AUTOSAR XML (schema 00049)
package /Systems
  system SYSTEM_XDIS: container-i-pdu-header-byte-order=big-endian, ecu-extract-version=2023.29.00, pnc-vector-length=7, pnc-vector-offset=1, system-version=2023.29.00
    system mapping SYSTEM_XDIS_MPPNG
      data-mappings:
        sender-receiver-to-signal-mapping={data-element=ECU_RBTM_FL_STAR_3_2020_ST3.R_PN14_ProdMd_Stat_ST3.PN14_ProdMd_Stat_ST3, system-signal=PN14_ProdMd_Stat_ST3}
        sender-receiver-to-signal-group-mapping={data-element=ECU_RBTM_FL_STAR_3_2020_ST3.R_PT4_PTCoor4_Pr5_ST3.PT4_PTCoor4_Pr5_ST3, signal-group=PT4_PTCoor4_Pr5_ST3_af4fxb1ykieox3itqdfzs0kpb, type-mapping=sender-rec-record-type-mapping=record-element-mappings=[{application-record-element=PT4_PTCoor_PT_Rdy_ST3, system-signal=PT4_PTCoor_PT_Rdy_ST3}, {application-record-element=PT4_PTCoor_EngStartPN14_Stat_ST3, system-signal=PT4_PTCoor_EngStartPN14_Stat_ST3}]}
        sender-receiver-to-signal-mapping={variation-point=post-build-variant-condition{matching-criterion=SideAllocation, value=0}, data-element=ECU_RBTM_FL_STAR_3_2020_ST3.P_RBTMFL_SP_ActvClient_ST35.RBTMFL_SP_ActvClient_ST35, system-signal=RBTMFL_SP_ActvClient_ST35}
        sender-receiver-to-signal-group-mapping={data-element=ECU_RBTM_FL_STAR_3_2020_ST3.R_EVC_CfgList_01_08_Pr5_ST3.EVC_CfgList_01_08_Pr5_ST3, signal-group=EVC_CfgList_01_08_Pr5_ST3_co3q1mwsf7pwxo2ix5jryc04x, type-mapping=sender-rec-record-type-mapping=record-element-mappings=[{application-record-element=EVC_List03_StStyle_ST3, system-signal=EVC_List03_StStyle_ST3}, {application-record-element=EVC_CfgList_01_08_Stat_ST3, system-signal=EVC_CfgList_01_08_Stat_ST3}]}
        sender-receiver-to-signal-mapping={data-element=ECU_RBTM_FL_STAR_3_2020_ST3.R_VehSpd_Disp_ST3.VehSpd_Disp_ST3, system-signal=VehSpd_Disp_ST3}
        sender-receiver-to-signal-mapping={variation-point=post-build-variant-condition{matching-criterion=SideAllocation, value=0}, data-element=ECU_RBTM_FL_STAR_3_2020_ST3.P_Awake_Ignition_On_RBTM_FL_ST3.Awake_Ignition_On_RBTM_FL_ST3, system-signal=Awake_Ignition_On_RBTM_FL_ST3}
        sender-receiver-to-signal-mapping={variation-point=post-build-variant-condition{matching-criterion=SideAllocation, value=0}, data-element=ECU_RBTM_FL_STAR_3_2020_ST3.R_RevBltTns_FR_SafeCyc_Actv_ST3.RevBltTns_FR_SafeCyc_Actv_ST3, system-signal=RevBltTns_FR_SafeCyc_Actv_ST3}
        sender-receiver-to-signal-mapping={data-element=ECU_RBTM_FL_STAR_3_2020_ST3.R_DidA_ExtTest_Pres_ST3.DidA_ExtTest_Pres_ST3, system-signal=DidA_ExtTest_Pres_ST3}
        sender-receiver-to-signal-group-mapping={data-element=ECU_RBTM_FL_STAR_3_2020_ST3.R_PT4_PTCoor_DrvPosn_Gear_Pr5_ST3.PT4_PTCoor_DrvPosn_Gear_Pr5_ST3, signal-group=PT4_PTCoor_DrvPosn_Gear_Pr5_ST3_5p8cvrni3ypvuac33rj2asfy9, type-mapping=sender-rec-record-type-mapping=sender-rec-record-element-mapping{application-record-element=PT4_PTCoor_DrvPosn_Stat_ST3, system-signal=PT4_PTCoor_DrvPosn_Stat_ST3}}
        sender-receiver-to-signal-group-mapping={data-element=ECU_RBTM_FL_STAR_3_2020_ST3.R_ADAS_Posn_ST3.ADAS_Posn_ST3, signal-group=ADAS_Posn_ST3_cre9f2x2lehhx0k4gxnl4u9sg, type-mapping=sender-rec-record-type-mapping=record-element-mappings=[{application-record-element=ADAS_Posn_Idx_ST3, system-signal=ADAS_Posn_Idx_ST3}, {application-record-element=ADAS_Posn_Offset_ST3, system-signal=ADAS_Posn_Offset_ST3}, {application-record-element=ADAS_Posn_Age_ST3, system-signal=ADAS_Posn_Age_ST3}, {application-record-element=ADAS_Posn_Spd_ST3, system-signal=ADAS_Posn_Spd_ST3}, {application-record-element=ADAS_Posn_PathIdx_ST3, system-signal=ADAS_Posn_PathIdx_ST3}]}
        sender-receiver-to-signal-mapping={data-element=ECU_RBTM_FL_STAR_3_2020_ST3.R_ADAS_Prediction_MsgTyp_ST3.ADAS_Prediction_MsgTyp_ST3, system-signal=ADAS_Prediction_MsgTyp_ST3}
        sender-receiver-to-signal-mapping={variation-point=post-build-variant-condition{matching-criterion=SideAllocation, value=0}, data-element=ECU_RBTM_FL_STAR_3_2020_ST3.R_PS_Curve_FL_Rq_HU_ST3.PS_Curve_FL_Rq_HU_ST3, system-signal=PS_Curve_FL_Rq_HU_ST3}
        sender-receiver-to-signal-mapping={variation-point=post-build-variant-condition{matching-criterion=SideAllocation, value=0}, data-element=ECU_RBTM_FL_STAR_3_2020_ST3.P_RevBltTns_FL_ComCyc_Actv_ST3.RevBltTns_FL_ComCyc_Actv_ST3, system-signal=RevBltTns_FL_ComCyc_Actv_ST3}
        sender-receiver-to-signal-group-mapping={data-element=ECU_RBTM_FL_STAR_3_2020_ST3.R_ORC_Impact3_Pr5_ST3.ORC_Impact3_Pr5_ST3, signal-group=ORC_Impact3_Pr5_ST3_c4pqnkonfjwv3uiohsxhe9dwu, type-mapping=sender-rec-record-type-mapping=record-element-mappings=[{application-record-element=Impact_S2_ST3, system-signal=Impact_S2_ST3}, {application-record-element=Impact_RO_type2_ST3, system-signal=Impact_RO_type2_ST3}, {application-record-element=Impact_F2_ST3, system-signal=Impact_F2_ST3}, {application-record-element=Impact_F1_ST3, system-signal=Impact_F1_ST3}, {application-record-element=Impact_X_ST3, system-signal=Impact_X_ST3}, {application-record-element=SQC_ORC_Impact3_Pr5_ST3, system-signal=SQC_ORC_Impact3_Pr5_ST3}, {application-record-element=Impact_F3_ST3, system-signal=Impact_F3_ST3}, {application-record-element=Impact_RO_type1_ST3, system-signal=Impact_RO_type1_ST3}, {application-record-element=Impact_S1_ST3, system-signal=Impact_S1_ST3}, {application-record-element=CRC_ORC_Impact3_Pr5_ST3, system-signal=CRC_ORC_Impact3_Pr5_ST3}]}
        sender-receiver-to-signal-group-mapping={data-element=ECU_RBTM_FL_STAR_3_2020_ST3.R_VSS_TP_Auth_ST3.VSS_TP_Auth_ST3, signal-group=VSS_TP_Auth_ST3_6j4id7sghlvlbroli4wjozjik, type-mapping=sender-rec-array-type-mapping=array-element-mappings=[{indexed-array-element={application-array-element=ARRAY_ELEMENT, index=0}, system-signal=VSS_TP_Auth_0_ST3}, {indexed-array-element={application-array-element=ARRAY_ELEMENT, index=1}, system-signal=VSS_TP_Auth_1_ST3}, {indexed-array-element={application-array-element=ARRAY_ELEMENT, index=2}, system-signal=VSS_TP_Auth_2_ST3}, {indexed-array-element={application-array-element=ARRAY_ELEMENT, index=3}, system-signal=VSS_TP_Auth_3_ST3}, {indexed-array-element={application-array-element=ARRAY_ELEMENT, index=4}, system-signal=VSS_TP_Auth_4_ST3}, {indexed-array-element={application-array-element=ARRAY_ELEMENT, index=5}, system-signal=VSS_TP_Auth_5_ST3}, {indexed-array-element={application-array-element=ARRAY_ELEMENT, index=6}, system-signal=VSS_TP_Auth_6_ST3}, {indexed-array-element={application-array-element=ARRAY_ELEMENT, index=7}, system-signal=VSS_TP_Auth_7_ST3}]}
        sender-receiver-to-signal-mapping={data-element=ECU_RBTM_FL_STAR_3_2020_ST3.R_PN14_DDP_Sw_Stat_ST3.PN14_DDP_Sw_Stat_ST3, system-signal=PN14_DDP_Sw_Stat_ST3}
        sender-receiver-to-signal-mapping={data-element=ECU_RBTM_FL_STAR_3_2020_ST3.R_Navi_RouteGuidance_Stat_ST3.Navi_RouteGuidance_Stat_ST3, system-signal=Navi_RouteGuidance_Stat_ST3}
        sender-receiver-to-signal-group-mapping={data-element=ECU_RBTM_FL_STAR_3_2020_ST3.R_DI_Odo_Pr5_ST3.DI_Odo_Pr5_ST3, signal-group=DI_Odo_Pr5_ST3_e68xmtlkywxgxsdwekdjjhw3t, type-mapping=sender-rec-record-type-mapping=sender-rec-record-element-mapping{application-record-element=Odo_ST3, system-signal=Odo_ST3}}
        sender-receiver-to-signal-mapping={variation-point=post-build-variant-condition{matching-criterion=SideAllocation, value=0}, data-element=ECU_RBTM_FL_STAR_3_2020_ST3.P_BltSlckDec_Md_XX_Stat_ST3.BltSlckDec_Md_XX_Stat_ST3, system-signal=BltSlckDec_Md_FL_Stat_ST3}
        sender-receiver-to-signal-mapping={variation-point=post-build-variant-condition{matching-criterion=SideAllocation, value=0}, data-element=ECU_RBTM_FL_STAR_3_2020_ST3.P_RevBltTns_FL_SafeCyc_Actv_ST3.RevBltTns_FL_SafeCyc_Actv_ST3, system-signal=RevBltTns_FL_SafeCyc_Actv_ST3}
        sender-receiver-to-signal-mapping={data-element=ECU_RBTM_FL_STAR_3_2020_ST3.R_PN14_TransMd_Stat_ST3.PN14_TransMd_Stat_ST3, system-signal=PN14_TransMd_Stat_ST3}
        sender-receiver-to-signal-group-mapping={data-element=ECU_RBTM_FL_STAR_3_2020_ST3.R_VSS_TP_RealTmOffset_ST3.VSS_TP_RealTmOffset_ST3, signal-group=VSS_TP_RealTmOffset_ST3_1t7vc44gftc0wv35k5kgc2in9, type-mapping=sender-rec-array-type-mapping=array-element-mappings=[{indexed-array-element={application-array-element=ARRAY_ELEMENT, index=0}, system-signal=VSS_TP_RealTmOffset_0_ST3}, {indexed-array-element={application-array-element=ARRAY_ELEMENT, index=1}, system-signal=VSS_TP_RealTmOffset_1_ST3}, {indexed-array-element={application-array-element=ARRAY_ELEMENT, index=2}, system-signal=VSS_TP_RealTmOffset_2_ST3}, {indexed-array-element={application-array-element=ARRAY_ELEMENT, index=3}, system-signal=VSS_TP_RealTmOffset_3_ST3}, {indexed-array-element={application-array-element=ARRAY_ELEMENT, index=4}, system-signal=VSS_TP_RealTmOffset_4_ST3}, {indexed-array-element={application-array-element=ARRAY_ELEMENT, index=5}, system-signal=VSS_TP_RealTmOffset_5_ST3}, {indexed-array-element={application-array-element=ARRAY_ELEMENT, index=6}, system-signal=VSS_TP_RealTmOffset_6_ST3}, {indexed-array-element={application-array-element=ARRAY_ELEMENT, index=7}, system-signal=VSS_TP_RealTmOffset_7_ST3}]}
        sender-receiver-to-signal-group-mapping={data-element=ECU_RBTM_FL_STAR_3_2020_ST3.R_PT4_PTCoor9_Pr5_ST3.PT4_PTCoor9_Pr5_ST3, signal-group=PT4_PTCoor9_Pr5_ST3_6r95o81sst3tk9w2lzz600cw3, type-mapping=sender-rec-record-type-mapping=sender-rec-record-element-mapping{application-record-element=PT4_PTCoor_Accel_Md_ST3, system-signal=PT4_PTCoor_Accel_Md_ST3}}
        sender-receiver-to-signal-mapping={variation-point=post-build-variant-condition{matching-criterion=SideAllocation, value=0}, data-element=ECU_RBTM_FL_STAR_3_2020_ST3.P_RBTM_FL_Disp_Rq_ST3.RBTM_FL_Disp_Rq_ST3, system-signal=RBTM_FL_Disp_Rq_ST3}
        sender-receiver-to-signal-mapping={variation-point=post-build-variant-condition{matching-criterion=SideAllocation, value=0}, data-element=ECU_RBTM_FL_STAR_3_2020_ST3.P_PS_Curve_FL_Stat_ST3.PS_Curve_FL_Stat_ST3, system-signal=PS_Curve_FL_Stat_ST3}
        sender-receiver-to-signal-mapping={variation-point=post-build-variant-condition{matching-criterion=SideAllocation, value=0}, data-element=ECU_RBTM_FL_STAR_3_2020_ST3.R_BeltHdOvr_XX_Stat_ST3.BeltHdOvr_XX_Stat_ST3, system-signal=BeltHdOvr_FL_Stat_ST3}
        sender-receiver-to-signal-mapping={variation-point=post-build-variant-condition{matching-criterion=SideAllocation, value=0}, data-element=ECU_RBTM_FL_STAR_3_2020_ST3.P_ECU_Id_RBTM_FL_ST3.ECU_Id_RBTM_FL_ST3, system-signal=ECU_Id_RBTM_FL_ST3}
        sender-receiver-to-signal-group-mapping={variation-point=post-build-variant-condition{matching-criterion=SideAllocation, value=0}, data-element=ECU_RBTM_FL_STAR_3_2020_ST3.P_ROE.ROE_XX_ST3, signal-group=ROE_RBTM_FL_ST3_6e0rxnifai2txra0wamb18g4m, type-mapping=sender-rec-record-type-mapping=record-element-mappings=[{application-record-element=ROE_0, system-signal=ROE_0_RBTM_FL_ST3}, {application-record-element=ROE_4, system-signal=ROE_4_RBTM_FL_ST3}, {application-record-element=ROE_3, system-signal=ROE_3_RBTM_FL_ST3}, {application-record-element=ROE_1, system-signal=ROE_1_RBTM_FL_ST3}, {application-record-element=ROE_2, system-signal=ROE_2_RBTM_FL_ST3}, {application-record-element=ROE_5, system-signal=ROE_5_RBTM_FL_ST3}, {application-record-element=ROE_6, system-signal=ROE_6_RBTM_FL_ST3}, {application-record-element=ROE_7, system-signal=ROE_7_RBTM_FL_ST3}]}
        sender-receiver-to-signal-group-mapping={data-element=ECU_RBTM_FL_STAR_3_2020_ST3.R_Bckl_Sw_Fx_Stat_Pr5_ST3.Bckl_Sw_Fx_Stat_Pr5_ST3, signal-group=Bckl_Sw_Fx_Stat_Pr5_ST3_dihag5a55iw4h5qk539fx0kup, type-mapping=sender-rec-record-type-mapping=record-element-mappings=[{application-record-element=Rsrv1_Bckl_Sw_Fx_Stat_ST3, system-signal=Rsrv1_Bckl_Sw_Fx_Stat_ST3}, {application-record-element=Bckl_Sw_D_Stat_ST3, system-signal=Bckl_Sw_D_Stat_ST3}, {application-record-element=Bckl_Sw_FP_Stat_ST3, system-signal=Bckl_Sw_FP_Stat_ST3}, {application-record-element=CRC_Bckl_Sw_Fx_Stat_Pr5_ST3, system-signal=CRC_Bckl_Sw_Fx_Stat_Pr5_ST3}, {application-record-element=SQC_Bckl_Sw_Fx_Stat_Pr5_ST3, system-signal=SQC_Bckl_Sw_Fx_Stat_Pr5_ST3}]}
        sender-receiver-to-signal-mapping={data-element=ECU_RBTM_FL_STAR_3_2020_ST3.R_PN14_SupBat_Volt_ST3.PN14_SupBat_Volt_ST3, system-signal=PN14_SupBat_Volt_ST3}
        sender-receiver-to-signal-mapping={variation-point=post-build-variant-condition{matching-criterion=SideAllocation, value=0}, data-element=ECU_RBTM_FL_STAR_3_2020_ST3.R_RevBltTns_FR_ComCyc_Actv_ST3.RevBltTns_FR_ComCyc_Actv_ST3, system-signal=RevBltTns_FR_ComCyc_Actv_ST3}
        sender-receiver-to-signal-mapping={variation-point=post-build-variant-condition{matching-criterion=SideAllocation, value=0}, data-element=ECU_RBTM_FL_STAR_3_2020_ST3.P_RBTMFL_SP_FctPrecond_Stat_ST35.RBTMFL_SP_FctPrecond_Stat_ST35, system-signal=RBTMFL_SP_FctPrecond_Stat_ST35}
        sender-receiver-to-signal-mapping={variation-point=post-build-variant-condition{matching-criterion=SideAllocation, value=0}, data-element=ECU_RBTM_FL_STAR_3_2020_ST3.P_Awake_Diag_Actv_RBTM_FL_ST3.Awake_Diag_Actv_RBTM_FL_ST3, system-signal=Awake_Diag_Actv_RBTM_FL_ST3}
        sender-receiver-to-signal-group-mapping={data-element=ECU_RBTM_FL_STAR_3_2020_ST3.R_Ign_Stat_Pr5_ST3.Ign_Stat_Pr5_ST3, signal-group=Ign_Stat_Pr5_ST3_csgs1dv6drms80o1i9p49677w, type-mapping=sender-rec-record-type-mapping=record-element-mappings=[{application-record-element=KG_StartSw_Psd_ST3, system-signal=KG_StartSw_Psd_ST3}, {application-record-element=CRC_Ign_Stat_Pr5_ST3, system-signal=CRC_Ign_Stat_Pr5_ST3}, {application-record-element=Veh_Op_Mode_ST3, system-signal=Veh_Op_Mode_ST3}, {application-record-element=ISw_Stat_ST3, system-signal=ISw_Stat_ST3}, {application-record-element=SQC_Ign_Stat_Pr5_ST3, system-signal=SQC_Ign_Stat_Pr5_ST3}]}
        sender-receiver-to-signal-group-mapping={data-element=ECU_RBTM_FL_STAR_3_2020_ST3.R_VSS_TP_VIN_ST3.VSS_TP_VIN_ST3, signal-group=VSS_TP_VIN_ST3_bz1xsv84cxzl09j028gn39p69, type-mapping=sender-rec-array-type-mapping=array-element-mappings=[{indexed-array-element={application-array-element=ARRAY_ELEMENT, index=0}, system-signal=VSS_TP_VIN_0_ST3}, {indexed-array-element={application-array-element=ARRAY_ELEMENT, index=1}, system-signal=VSS_TP_VIN_1_ST3}, {indexed-array-element={application-array-element=ARRAY_ELEMENT, index=2}, system-signal=VSS_TP_VIN_2_ST3}, {indexed-array-element={application-array-element=ARRAY_ELEMENT, index=3}, system-signal=VSS_TP_VIN_3_ST3}, {indexed-array-element={application-array-element=ARRAY_ELEMENT, index=4}, system-signal=VSS_TP_VIN_4_ST3}, {indexed-array-element={application-array-element=ARRAY_ELEMENT, index=5}, system-signal=VSS_TP_VIN_5_ST3}, {indexed-array-element={application-array-element=ARRAY_ELEMENT, index=6}, system-signal=VSS_TP_VIN_6_ST3}, {indexed-array-element={application-array-element=ARRAY_ELEMENT, index=7}, system-signal=VSS_TP_VIN_7_ST3}]}
        sender-receiver-to-signal-group-mapping={data-element=ECU_RBTM_FL_STAR_3_2020_ST3.R_CLkS_DrRltch_Stat_Pr5_ST3.CLkS_DrRltch_Stat_Pr5_ST3, signal-group=CLkS_DrRltch_Stat_Pr5_ST3_7at68qvnk0r9npofyykyfq82v, type-mapping=sender-rec-record-type-mapping=record-element-mappings=[{application-record-element=DrRLtch_FL_Stat_ST3, system-signal=DrRLtch_FL_Stat_ST3}, {application-record-element=DrRLtch_FR_Stat_ST3, system-signal=DrRLtch_FR_Stat_ST3}]}
        sender-receiver-to-signal-mapping={variation-point=post-build-variant-condition{matching-criterion=SideAllocation, value=0}, data-element=ECU_RBTM_FL_STAR_3_2020_ST3.P_WakeupRsn_RBTM_FL_ST3.WakeupRsn_RBTM_FL_ST3, system-signal=WakeupRsn_RBTM_FL_ST3}
        sender-receiver-to-signal-group-mapping={data-element=ECU_RBTM_FL_STAR_3_2020_ST3.R_ADAS_Profile_Short_CurvLn_ST3.ADAS_Profile_Short_CurvLn_ST3, signal-group=ADAS_Profile_Short_CurvLn_ST3_96e9ejcafisp13h7moqj5malh, type-mapping=sender-rec-record-type-mapping=record-element-mappings=[{application-record-element=ADAS_ProfShort_Value0_CL_ST3, system-signal=ADAS_ProfShort_Value0_CL_ST3}, {application-record-element=ADAS_ProfShort_Dist1_CL_ST3, system-signal=ADAS_ProfShort_Dist1_CL_ST3}, {application-record-element=ADAS_ProfShort_PathIdx_CL_ST3, system-signal=ADAS_ProfShort_PathIdx_CL_ST3}, {application-record-element=ADAS_ProfShort_Value1_CL_ST3, system-signal=ADAS_ProfShort_Value1_CL_ST3}, {application-record-element=ADAS_ProfShort_Offset_CL_ST3, system-signal=ADAS_ProfShort_Offset_CL_ST3}, {application-record-element=ADAS_ProfShort_ReTr_CL_ST3, system-signal=ADAS_ProfShort_ReTr_CL_ST3}]}
        sender-receiver-to-signal-mapping={data-element=ECU_RBTM_FL_STAR_3_2020_ST3.R_ADAS_ProfShort_ProfTyp_ST3.ADAS_ProfShort_ProfTyp_ST3, system-signal=ADAS_ProfShort_ProfTyp_ST3}
        sender-receiver-to-signal-group-mapping={data-element=ECU_RBTM_FL_STAR_3_2020_ST3.R_ELC_Lvr_Stat_Pr5_ST3.ELC_Lvr_Stat_Pr5_ST3, signal-group=ELC_Lvr_Stat_Pr5_ST3_7b68ktfwrvsk1oyozi7cntryn, type-mapping=sender-rec-record-type-mapping=sender-rec-record-element-mapping{application-record-element=ELC_TurnIndLvr_Stat_ST3, system-signal=ELC_TurnIndLvr_Stat_ST3}}
        sender-receiver-to-signal-group-mapping={data-element=ECU_RBTM_FL_STAR_3_2020_ST3.R_PresfAct_Adj_Pr5_ST3.PresfAct_Adj_Pr5_ST3, signal-group=PresfAct_Adj_Pr5_ST3_2joar1a41xrgjqab60epnbplm, type-mapping=sender-rec-record-type-mapping=record-element-mappings=[{application-record-element=CRC_PresfAct_Adj_Pr5_ST3, system-signal=CRC_PresfAct_Adj_Pr5_ST3}, {application-record-element=Presf_FricCoeff_Estim_ST3, system-signal=Presf_FricCoeff_Estim_ST3}, {application-record-element=Presf_Snd_Rq_ST3, system-signal=Presf_Snd_Rq_ST3}, {application-record-element=Presf_Lvl_ST3, system-signal=Presf_Lvl_ST3}, {application-record-element=PresfAct_TensSupp_Rq_ST3, system-signal=PresfAct_TensSupp_Rq_ST3}, {application-record-element=PresfAccelReset_NotExcd_ST3, system-signal=PresfAccelReset_NotExcd_ST3}, {application-record-element=Presf_Fric_Fctr_Lo_ST3, system-signal=Presf_Fric_Fctr_Lo_ST3}, {application-record-element=Rsrv6_Presf_Adj_ST3, system-signal=Rsrv6_Presf_Adj_ST3}, {application-record-element=Presf_Enbl_ST3, system-signal=Presf_Enbl_ST3}, {application-record-element=PresfAct_Adj_Rq_ST3, system-signal=PresfAct_Adj_Rq_ST3}, {application-record-element=SQC_PresfAct_Adj_Pr5_ST3, system-signal=SQC_PresfAct_Adj_Pr5_ST3}]}
        sender-receiver-to-signal-group-mapping={data-element=ECU_RBTM_FL_STAR_3_2020_ST3.R_VSS_TP_SharedSecret_ST3.VSS_TP_SharedSecret_ST3, signal-group=VSS_TP_SharedSecret_ST3_8pj4t8t4rm3tw3pk5hj7vonti, type-mapping=sender-rec-array-type-mapping=array-element-mappings=[{indexed-array-element={application-array-element=ARRAY_ELEMENT, index=0}, system-signal=VSS_TP_SharedSecret_0_ST3}, {indexed-array-element={application-array-element=ARRAY_ELEMENT, index=1}, system-signal=VSS_TP_SharedSecret_1_ST3}, {indexed-array-element={application-array-element=ARRAY_ELEMENT, index=2}, system-signal=VSS_TP_SharedSecret_2_ST3}, {indexed-array-element={application-array-element=ARRAY_ELEMENT, index=3}, system-signal=VSS_TP_SharedSecret_3_ST3}, {indexed-array-element={application-array-element=ARRAY_ELEMENT, index=4}, system-signal=VSS_TP_SharedSecret_4_ST3}, {indexed-array-element={application-array-element=ARRAY_ELEMENT, index=5}, system-signal=VSS_TP_SharedSecret_5_ST3}, {indexed-array-element={application-array-element=ARRAY_ELEMENT, index=6}, system-signal=VSS_TP_SharedSecret_6_ST3}, {indexed-array-element={application-array-element=ARRAY_ELEMENT, index=7}, system-signal=VSS_TP_SharedSecret_7_ST3}]}
        sender-receiver-to-signal-group-mapping={data-element=ECU_RBTM_FL_STAR_3_2020_ST3.R_DPC_Md_Rq_ESP_Pr5_ST3.DPC_Md_Rq_ESP_Pr5_ST3, signal-group=DPC_Md_Rq_ESP_Pr5_ST3_dcsny138uwpesz5bmssj1scqi, type-mapping=sender-rec-record-type-mapping=sender-rec-record-element-mapping{application-record-element=DPC_Md_PT_Rq_ST3, system-signal=DPC_Md_PT_Rq_ST3}}
        sender-receiver-to-signal-group-mapping={variation-point=post-build-variant-condition{matching-criterion=SideAllocation, value=0}, data-element=ECU_RBTM_FL_STAR_3_2020_ST3.P_Meas_RBTM_FL_ST3.Meas8_RBTM_FL_ST3, signal-group=Meas8_RBTM_FL_ST3_72jyquhuktrmjm0hkqempja37, type-mapping=sender-rec-record-type-mapping=record-element-mappings=[{application-record-element=Meas_RBTM_FL_02, system-signal=Meas_RBTM_FL_02_ST3}, {application-record-element=Meas_RBTM_FL_08, system-signal=Meas_RBTM_FL_08_ST3}, {application-record-element=Meas_RBTM_FL_03, system-signal=Meas_RBTM_FL_03_ST3}, {application-record-element=Meas_RBTM_FL_06, system-signal=Meas_RBTM_FL_06_ST3}, {application-record-element=Meas_RBTM_FL_04, system-signal=Meas_RBTM_FL_04_ST3}, {application-record-element=Meas_RBTM_FL_07, system-signal=Meas_RBTM_FL_07_ST3}, {application-record-element=Meas_RBTM_FL_05, system-signal=Meas_RBTM_FL_05_ST3}, {application-record-element=Meas_RBTM_FL_01, system-signal=Meas_RBTM_FL_01_ST3}]}
        sender-receiver-to-signal-group-mapping={data-element=ECU_RBTM_FL_STAR_3_2020_ST3.R_ORC_Impact2_Pr5_ST3.ORC_Impact2_Pr5_ST3, signal-group=ORC_Impact2_Pr5_ST3_b9l09rrslyv7vj3o92j69irnd, type-mapping=sender-rec-record-type-mapping=sender-rec-record-element-mapping{application-record-element=Impact_Y_ST3, system-signal=Impact_Y_ST3}}
        sender-receiver-to-signal-mapping={variation-point=post-build-variant-condition{matching-criterion=SideAllocation, value=0}, data-element=ECU_RBTM_FL_STAR_3_2020_ST3.P_RBTMFL_Actv_Lvl_ST35.RBTMFL_Actv_Lvl_ST35, system-signal=RBTMFL_Actv_Lvl_ST35}
        sender-receiver-to-signal-group-mapping={variation-point=post-build-variant-condition{matching-criterion=SideAllocation, value=0}, data-element=ECU_RBTM_FL_STAR_3_2020_ST3.R_Develop8_Rq_RBTM_FL_ST3.Develop8_Rq_RBTM_FL_ST3, signal-group=Develop8_Rq_RBTM_FL_ST3_48g6nu8rjjp9s4bhq1x3pz06u, type-mapping=sender-rec-record-type-mapping=record-element-mappings=[{application-record-element=Develop_Rq_RBTM_FL_01, system-signal=Develop_Rq_RBTM_FL_01_ST3}, {application-record-element=Develop_Rq_RBTM_FL_03, system-signal=Develop_Rq_RBTM_FL_03_ST3}, {application-record-element=Develop_Rq_RBTM_FL_04, system-signal=Develop_Rq_RBTM_FL_04_ST3}, {application-record-element=Develop_Rq_RBTM_FL_02, system-signal=Develop_Rq_RBTM_FL_02_ST3}, {application-record-element=Develop_Rq_RBTM_FL_07, system-signal=Develop_Rq_RBTM_FL_07_ST3}, {application-record-element=Develop_Rq_RBTM_FL_08, system-signal=Develop_Rq_RBTM_FL_08_ST3}, {application-record-element=Develop_Rq_RBTM_FL_06, system-signal=Develop_Rq_RBTM_FL_06_ST3}, {application-record-element=Develop_Rq_RBTM_FL_05, system-signal=Develop_Rq_RBTM_FL_05_ST3}]}
        sender-receiver-to-signal-group-mapping={variation-point=post-build-variant-condition{matching-criterion=SideAllocation, value=0}, data-element=ECU_RBTM_FL_STAR_3_2020_ST3.P_Develop8_Rs_RBTM_FL_ST3.Develop8_Rs_RBTM_FL_ST3, signal-group=Develop8_Rs_RBTM_FL_ST3_7jg1r8p1skn6yj1t9z2s157vt, type-mapping=sender-rec-record-type-mapping=record-element-mappings=[{application-record-element=Develop_Rs_RBTM_FL_04, system-signal=Develop_Rs_RBTM_FL_04_ST3}, {application-record-element=Develop_Rs_RBTM_FL_02, system-signal=Develop_Rs_RBTM_FL_02_ST3}, {application-record-element=Develop_Rs_RBTM_FL_08, system-signal=Develop_Rs_RBTM_FL_08_ST3}, {application-record-element=Develop_Rs_RBTM_FL_05, system-signal=Develop_Rs_RBTM_FL_05_ST3}, {application-record-element=Develop_Rs_RBTM_FL_03, system-signal=Develop_Rs_RBTM_FL_03_ST3}, {application-record-element=Develop_Rs_RBTM_FL_06, system-signal=Develop_Rs_RBTM_FL_06_ST3}, {application-record-element=Develop_Rs_RBTM_FL_01, system-signal=Develop_Rs_RBTM_FL_01_ST3}, {application-record-element=Develop_Rs_RBTM_FL_07, system-signal=Develop_Rs_RBTM_FL_07_ST3}]}
        sender-receiver-to-signal-mapping={variation-point=post-build-variant-condition{matching-criterion=SideAllocation, value=0}, data-element=ECU_RBTM_FL_STAR_3_2020_ST3.P_Awake_NwStart_RBTM_FL_ST3.Awake_NwStart_RBTM_FL_ST3, system-signal=Awake_NwStart_RBTM_FL_ST3}
        sender-receiver-to-signal-mapping={variation-point=post-build-variant-condition{matching-criterion=SideAllocation, value=0}, data-element=ECU_RBTM_FL_STAR_3_2020_ST3.P_RBTM_FL_Tgl_ST3.RBTM_FL_Tgl_ST3, system-signal=RBTM_FL_Tgl_ST3}
        sender-receiver-to-signal-group-mapping={data-element=ECU_RBTM_FL_STAR_3_2020_ST3.R_ADAS_Meta_ST3.ADAS_Meta_ST3, signal-group=ADAS_Meta_ST3_40sly585w5zu8pqjwib3nr7y7, type-mapping=sender-rec-record-type-mapping=record-element-mappings=[{application-record-element=ADAS_Meta_CountryCode_ST3, system-signal=ADAS_Meta_CountryCode_ST3}, {application-record-element=ADAS_Meta_RegionCode_ST3, system-signal=ADAS_Meta_RegionCode_ST3}]}
        sender-receiver-to-signal-mapping={data-element=ECU_RBTM_FL_STAR_3_2020_ST3.R_BltSlckDec_Md_Rq_HU_ST3.BltSlckDec_Md_Rq_HU_ST3, system-signal=BltSlckDec_Md_Rq_HU_ST3}
        sender-receiver-to-signal-group-mapping={data-element=ECU_RBTM_FL_STAR_3_2020_ST3.R_VSS_TP_SecTickCount_ST3.VSS_TP_SecTickCount_ST3, signal-group=VSS_TP_SecTickCount_Lvl2_ST3_9eubq13iosat764o0lqh5xb6r, type-mapping=sender-rec-array-type-mapping=array-element-mappings=[{indexed-array-element={application-array-element=ARRAY_ELEMENT, index=0}, system-signal=VSS_TP_SecTickCount_Lvl2_0_ST3}, {indexed-array-element={application-array-element=ARRAY_ELEMENT, index=1}, system-signal=VSS_TP_SecTickCount_Lvl2_1_ST3}, {indexed-array-element={application-array-element=ARRAY_ELEMENT, index=2}, system-signal=VSS_TP_SecTickCount_Lvl2_2_ST3}, {indexed-array-element={application-array-element=ARRAY_ELEMENT, index=3}, system-signal=VSS_TP_SecTickCount_Lvl2_3_ST3}, {indexed-array-element={application-array-element=ARRAY_ELEMENT, index=4}, system-signal=VSS_TP_SecTickCount_Lvl2_4_ST3}, {indexed-array-element={application-array-element=ARRAY_ELEMENT, index=5}, system-signal=VSS_TP_SecTickCount_Lvl2_5_ST3}, {indexed-array-element={application-array-element=ARRAY_ELEMENT, index=6}, system-signal=VSS_TP_SecTickCount_Lvl2_6_ST3}, {indexed-array-element={application-array-element=ARRAY_ELEMENT, index=7}, system-signal=VSS_TP_SecTickCount_Lvl2_7_ST3}]}
        sender-receiver-to-signal-group-mapping={data-element=ECU_RBTM_FL_STAR_3_2020_ST3.R_SBeltTens_SP_Lvl_Pr5_ST3.SBeltTens_SP_Lvl_Pr5_ST3, signal-group=SBeltTens_SP_Lvl_Pr5_ST3_4tqpkri37441o5ht9g9ekmyzh, type-mapping=sender-rec-record-type-mapping=record-element-mappings=[{application-record-element=SQC_SBeltTens_SP_Lvl_Pr5_ST3, system-signal=SQC_SBeltTens_SP_Lvl_Pr5_ST3}, {application-record-element=RBTMFR_SP_Lvl_Rq_ST35, system-signal=RBTMFR_SP_Lvl_Rq_ST35}, {application-record-element=Rsrv0_SBeltTens_SP_Lvl_Pr5_ST3, system-signal=Rsrv0_SBeltTens_SP_Lvl_Pr5_ST3}, {application-record-element=RBTMFL_SP_Lvl_Rq_ST35, system-signal=RBTMFL_SP_Lvl_Rq_ST35}, {application-record-element=CRC_SBeltTens_SP_Lvl_Pr5_ST3, system-signal=CRC_SBeltTens_SP_Lvl_Pr5_ST3}]}
        sender-receiver-to-signal-mapping={variation-point=post-build-variant-condition{matching-criterion=SideAllocation, value=1}, data-element=ECU_RBTM_FL_STAR_3_2020_ST3.P_RBTMFR_SP_ActvClient_ST35.RBTMFR_SP_ActvClient_ST35, system-signal=RBTMFR_SP_ActvClient_ST35}
        sender-receiver-to-signal-mapping={variation-point=post-build-variant-condition{matching-criterion=SideAllocation, value=1}, data-element=ECU_RBTM_FL_STAR_3_2020_ST3.R_RevBltTns_FL_SafeCyc_Actv_ST3.RevBltTns_FL_SafeCyc_Actv_ST3, system-signal=RevBltTns_FL_SafeCyc_Actv_ST3}
        sender-receiver-to-signal-mapping={variation-point=post-build-variant-condition{matching-criterion=SideAllocation, value=1}, data-element=ECU_RBTM_FL_STAR_3_2020_ST3.P_RBTMFR_SP_FctPrecond_Stat_ST35.RBTMFR_SP_FctPrecond_Stat_ST35, system-signal=RBTMFR_SP_FctPrecond_Stat_ST35}
        sender-receiver-to-signal-mapping={variation-point=post-build-variant-condition{matching-criterion=SideAllocation, value=1}, data-element=ECU_RBTM_FL_STAR_3_2020_ST3.P_RevBltTns_FR_SafeCyc_Actv_ST3.RevBltTns_FR_SafeCyc_Actv_ST3, system-signal=RevBltTns_FR_SafeCyc_Actv_ST3}
        sender-receiver-to-signal-mapping={variation-point=post-build-variant-condition{matching-criterion=SideAllocation, value=1}, data-element=ECU_RBTM_FL_STAR_3_2020_ST3.P_ECU_Id_RBTM_FR_ST3.ECU_Id_RBTM_FR_ST3, system-signal=ECU_Id_RBTM_FR_ST3}
        sender-receiver-to-signal-mapping={variation-point=post-build-variant-condition{matching-criterion=SideAllocation, value=1}, data-element=ECU_RBTM_FL_STAR_3_2020_ST3.P_Awake_Ignition_On_RBTM_FR_ST3.Awake_Ignition_On_RBTM_FR_ST3, system-signal=Awake_Ignition_On_RBTM_FR_ST3}
        sender-receiver-to-signal-mapping={variation-point=post-build-variant-condition{matching-criterion=SideAllocation, value=1}, data-element=ECU_RBTM_FL_STAR_3_2020_ST3.P_PS_Curve_FR_Stat_ST3.PS_Curve_FR_Stat_ST3, system-signal=PS_Curve_FR_Stat_ST3}
        sender-receiver-to-signal-mapping={variation-point=post-build-variant-condition{matching-criterion=SideAllocation, value=1}, data-element=ECU_RBTM_FL_STAR_3_2020_ST3.P_Awake_NwStart_RBTM_FR_ST3.Awake_NwStart_RBTM_FR_ST3, system-signal=Awake_NwStart_RBTM_FR_ST3}
        sender-receiver-to-signal-mapping={variation-point=post-build-variant-condition{matching-criterion=SideAllocation, value=1}, data-element=ECU_RBTM_FL_STAR_3_2020_ST3.P_BltSlckDec_Md_XX_Stat_ST3.BltSlckDec_Md_XX_Stat_ST3, system-signal=BltSlckDec_Md_FR_Stat_ST3}
        sender-receiver-to-signal-group-mapping={variation-point=post-build-variant-condition{matching-criterion=SideAllocation, value=1}, data-element=ECU_RBTM_FL_STAR_3_2020_ST3.P_Meas_RBTM_FR_ST3.Meas8_RBTM_FR_ST3, signal-group=Meas8_RBTM_FR_ST3_7ba3lhjy9fnhufd3n9dyw0p9p, type-mapping=sender-rec-record-type-mapping=record-element-mappings=[{application-record-element=Meas_RBTM_FR_05, system-signal=Meas_RBTM_FR_05_ST3}, {application-record-element=Meas_RBTM_FR_07, system-signal=Meas_RBTM_FR_07_ST3}, {application-record-element=Meas_RBTM_FR_02, system-signal=Meas_RBTM_FR_02_ST3}, {application-record-element=Meas_RBTM_FR_08, system-signal=Meas_RBTM_FR_08_ST3}, {application-record-element=Meas_RBTM_FR_03, system-signal=Meas_RBTM_FR_03_ST3}, {application-record-element=Meas_RBTM_FR_06, system-signal=Meas_RBTM_FR_06_ST3}, {application-record-element=Meas_RBTM_FR_01, system-signal=Meas_RBTM_FR_01_ST3}, {application-record-element=Meas_RBTM_FR_04, system-signal=Meas_RBTM_FR_04_ST3}]}
        sender-receiver-to-signal-mapping={variation-point=post-build-variant-condition{matching-criterion=SideAllocation, value=1}, data-element=ECU_RBTM_FL_STAR_3_2020_ST3.R_PS_Curve_FR_Rq_HU_ST3.PS_Curve_FR_Rq_HU_ST3, system-signal=PS_Curve_FR_Rq_HU_ST3}
        sender-receiver-to-signal-mapping={variation-point=post-build-variant-condition{matching-criterion=SideAllocation, value=1}, data-element=ECU_RBTM_FL_STAR_3_2020_ST3.P_RBTMFR_Actv_Lvl_ST35.RBTMFR_Actv_Lvl_ST35, system-signal=RBTMFR_Actv_Lvl_ST35}
        sender-receiver-to-signal-mapping={variation-point=post-build-variant-condition{matching-criterion=SideAllocation, value=1}, data-element=ECU_RBTM_FL_STAR_3_2020_ST3.R_RevBltTns_FL_ComCyc_Actv_ST3.RevBltTns_FL_ComCyc_Actv_ST3, system-signal=RevBltTns_FL_ComCyc_Actv_ST3}
        sender-receiver-to-signal-mapping={variation-point=post-build-variant-condition{matching-criterion=SideAllocation, value=1}, data-element=ECU_RBTM_FL_STAR_3_2020_ST3.P_RBTM_FR_Tgl_ST3.RBTM_FR_Tgl_ST3, system-signal=RBTM_FR_Tgl_ST3}
        sender-receiver-to-signal-mapping={variation-point=post-build-variant-condition{matching-criterion=SideAllocation, value=1}, data-element=ECU_RBTM_FL_STAR_3_2020_ST3.R_BeltHdOvr_XX_Stat_ST3.BeltHdOvr_XX_Stat_ST3, system-signal=BeltHdOvr_FR_Stat_ST3}
        sender-receiver-to-signal-group-mapping={variation-point=post-build-variant-condition{matching-criterion=SideAllocation, value=1}, data-element=ECU_RBTM_FL_STAR_3_2020_ST3.P_ROE.ROE_XX_ST3, signal-group=ROE_RBTM_FR_ST3_3f1btonh6ivdn6ytgyuu9rtt1, type-mapping=sender-rec-record-type-mapping=record-element-mappings=[{application-record-element=ROE_0, system-signal=ROE_0_RBTM_FR_ST3}, {application-record-element=ROE_4, system-signal=ROE_4_RBTM_FR_ST3}, {application-record-element=ROE_3, system-signal=ROE_3_RBTM_FR_ST3}, {application-record-element=ROE_1, system-signal=ROE_1_RBTM_FR_ST3}, {application-record-element=ROE_2, system-signal=ROE_2_RBTM_FR_ST3}, {application-record-element=ROE_5, system-signal=ROE_5_RBTM_FR_ST3}, {application-record-element=ROE_6, system-signal=ROE_6_RBTM_FR_ST3}, {application-record-element=ROE_7, system-signal=ROE_7_RBTM_FR_ST3}]}
        sender-receiver-to-signal-mapping={variation-point=post-build-variant-condition{matching-criterion=SideAllocation, value=1}, data-element=ECU_RBTM_FL_STAR_3_2020_ST3.P_WakeupRsn_RBTM_FR_ST3.WakeupRsn_RBTM_FR_ST3, system-signal=WakeupRsn_RBTM_FR_ST3}
        sender-receiver-to-signal-group-mapping={variation-point=post-build-variant-condition{matching-criterion=SideAllocation, value=1}, data-element=ECU_RBTM_FL_STAR_3_2020_ST3.P_Develop8_Rs_RBTM_FR_ST3.Develop8_Rs_RBTM_FR_ST3, signal-group=Develop8_Rs_RBTM_FR_ST3_5t18pq0a13t698v0vsj7yvmmm, type-mapping=sender-rec-record-type-mapping=record-element-mappings=[{application-record-element=Develop_Rs_RBTM_FR_07, system-signal=Develop_Rs_RBTM_FR_07_ST3}, {application-record-element=Develop_Rs_RBTM_FR_05, system-signal=Develop_Rs_RBTM_FR_05_ST3}, {application-record-element=Develop_Rs_RBTM_FR_02, system-signal=Develop_Rs_RBTM_FR_02_ST3}, {application-record-element=Develop_Rs_RBTM_FR_08, system-signal=Develop_Rs_RBTM_FR_08_ST3}, {application-record-element=Develop_Rs_RBTM_FR_04, system-signal=Develop_Rs_RBTM_FR_04_ST3}, {application-record-element=Develop_Rs_RBTM_FR_06, system-signal=Develop_Rs_RBTM_FR_06_ST3}, {application-record-element=Develop_Rs_RBTM_FR_01, system-signal=Develop_Rs_RBTM_FR_01_ST3}, {application-record-element=Develop_Rs_RBTM_FR_03, system-signal=Develop_Rs_RBTM_FR_03_ST3}]}
        sender-receiver-to-signal-mapping={variation-point=post-build-variant-condition{matching-criterion=SideAllocation, value=1}, data-element=ECU_RBTM_FL_STAR_3_2020_ST3.P_RBTM_FR_Disp_Rq_ST3.RBTM_FR_Disp_Rq_ST3, system-signal=RBTM_FR_Disp_Rq_ST3}
        sender-receiver-to-signal-group-mapping={variation-point=post-build-variant-condition{matching-criterion=SideAllocation, value=1}, data-element=ECU_RBTM_FL_STAR_3_2020_ST3.R_Develop8_Rq_RBTM_FR_ST3.Develop8_Rq_RBTM_FR_ST3, signal-group=Develop8_Rq_RBTM_FR_ST3_bcqj2sqez8u9spf5qxmu4a35u, type-mapping=sender-rec-record-type-mapping=record-element-mappings=[{application-record-element=Develop_Rq_RBTM_FR_02, system-signal=Develop_Rq_RBTM_FR_02_ST3}, {application-record-element=Develop_Rq_RBTM_FR_03, system-signal=Develop_Rq_RBTM_FR_03_ST3}, {application-record-element=Develop_Rq_RBTM_FR_05, system-signal=Develop_Rq_RBTM_FR_05_ST3}, {application-record-element=Develop_Rq_RBTM_FR_08, system-signal=Develop_Rq_RBTM_FR_08_ST3}, {application-record-element=Develop_Rq_RBTM_FR_04, system-signal=Develop_Rq_RBTM_FR_04_ST3}, {application-record-element=Develop_Rq_RBTM_FR_06, system-signal=Develop_Rq_RBTM_FR_06_ST3}, {application-record-element=Develop_Rq_RBTM_FR_07, system-signal=Develop_Rq_RBTM_FR_07_ST3}, {application-record-element=Develop_Rq_RBTM_FR_01, system-signal=Develop_Rq_RBTM_FR_01_ST3}]}
        sender-receiver-to-signal-mapping={variation-point=post-build-variant-condition{matching-criterion=SideAllocation, value=1}, data-element=ECU_RBTM_FL_STAR_3_2020_ST3.P_RevBltTns_FR_ComCyc_Actv_ST3.RevBltTns_FR_ComCyc_Actv_ST3, system-signal=RevBltTns_FR_ComCyc_Actv_ST3}
        sender-receiver-to-signal-mapping={variation-point=post-build-variant-condition{matching-criterion=SideAllocation, value=1}, data-element=ECU_RBTM_FL_STAR_3_2020_ST3.P_Awake_Diag_Actv_RBTM_FR_ST3.Awake_Diag_Actv_RBTM_FR_ST3, system-signal=Awake_Diag_Actv_RBTM_FR_ST3}
      pnc-mapping physical-channel=BODY3, pnc-group=[RBTM_FL_BODY3_Rx_PNC_All_Active, RBTM_FL_BODY3_Tx_PNC_All_Active], pnc-identifier=8, pnc-wakeup-enable=true, wakeup-frame=NM_RBTM_FL_ST3_77kue78kbv2ypznjo10wf8eeg, variation-point=post-build-variant-condition{matching-criterion=SideAllocation, value=0}:
        ident PNC_00_MAPPING
      pnc-mapping physical-channel=BODY3, pnc-group=[RBTM_FL_BODY3_Rx_PNC_20, RBTM_FL_BODY3_Tx_PNC_20], pnc-identifier=28, pnc-wakeup-enable=true, wakeup-frame=NM_RBTM_FL_ST3_77kue78kbv2ypznjo10wf8eeg, variation-point=post-build-variant-condition{matching-criterion=SideAllocation, value=0}:
        ident PNC_20_MAPPING
      pnc-mapping physical-channel=BODY3, pnc-group=[RBTM_FR_BODY3_Rx_PNC_All_Active, RBTM_FR_BODY3_Tx_PNC_All_Active], pnc-identifier=8, pnc-wakeup-enable=true, wakeup-frame=NM_RBTM_FR_ST3_bajjcwftbqyrjj3wbd4kw62kg, variation-point=post-build-variant-condition{matching-criterion=SideAllocation, value=1}:
        ident PNC_00_MAPPING
      pnc-mapping physical-channel=BODY3, pnc-group=[RBTM_FR_BODY3_Rx_PNC_20, RBTM_FR_BODY3_Tx_PNC_20], pnc-identifier=28, pnc-wakeup-enable=true, wakeup-frame=NM_RBTM_FR_ST3_bajjcwftbqyrjj3wbd4kw62kg, variation-point=post-build-variant-condition{matching-criterion=SideAllocation, value=1}:
        ident PNC_20_MAPPING
      sw-mappings:
        swc to ecu mapping XDIS_d1sw6wvepke5wdh6wz3wdsmd4: ecu-instance=RBTM_FL
          component:
            ECU_RBTM_FL_STAR_3_2020_ST3.BaseFunction_ECU_RBTM_FL_ST3
            ECU_RBTM_FL_STAR_3_2020_ST3.Diagnostics_RBTM_FL_ST3
            ECU_RBTM_FL_STAR_3_2020_ST3.PRESAFE_Function_Belt_Tensioner_Lt_ST3
            ECU_RBTM_FL_STAR_3_2020_ST3.SeatBeltComf_BeltAdj_FL_ST3
            ECU_RBTM_FL_STAR_3_2020_ST3.VSS_Slave_Lvl2_ST3
            ECU_RBTM_FL_STAR_3_2020_ST3.BaseFunction_ECU_RBTM_FR_ST3
            ECU_RBTM_FL_STAR_3_2020_ST3.Diagnostics_RBTM_FR_ST3
            ECU_RBTM_FL_STAR_3_2020_ST3.PRESAFE_Function_Belt_Tensioner_Rt_ST3
            ECU_RBTM_FL_STAR_3_2020_ST3.SeatBeltComf_BeltAdj_FR_ST3
    root-software-compositions:
      root sw composition prototype ECU_RBTM_FL_STAR_3_2020_ST3: software-composition=ECU_RBTM_FL_STAR_3_2020_ST3  # Reversibler Gurtstraffer vorne links / Reversible Belt Tensioner Front Left
package /SwComponentTypes
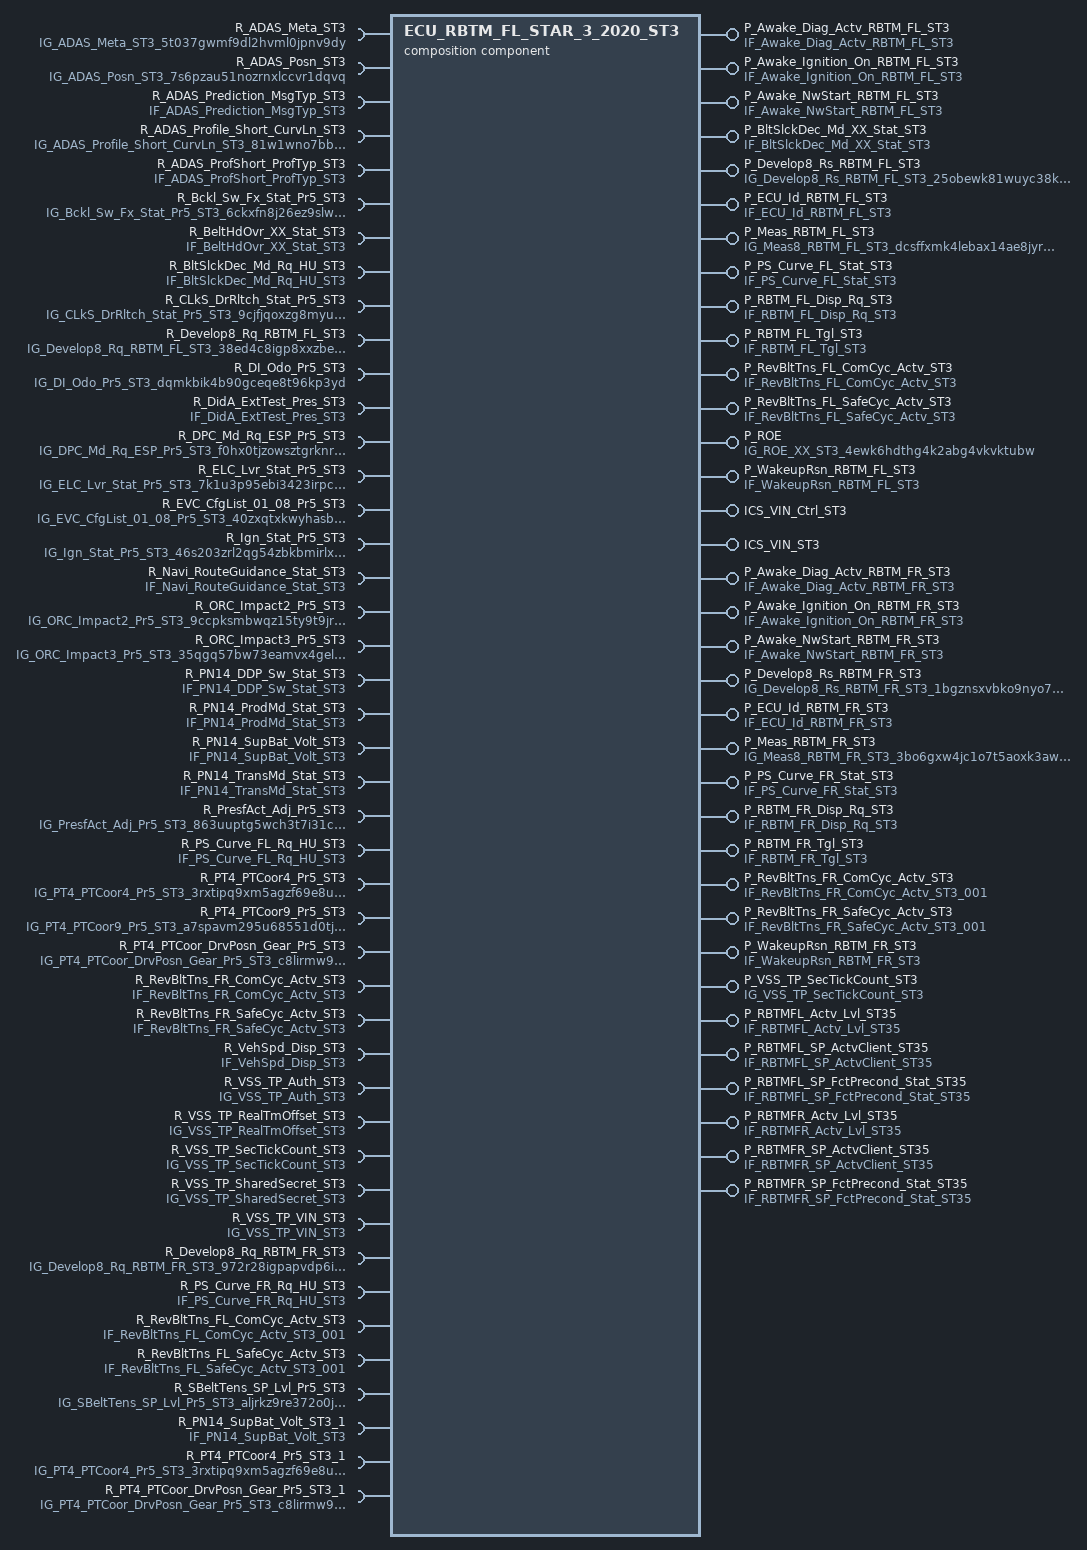
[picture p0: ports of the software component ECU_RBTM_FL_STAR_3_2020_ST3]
  composition sw component type ECU_RBTM_FL_STAR_3_2020_ST3: data-type-mapping=DATA_TYPE_MAPPING_SET  # Reversibler Gurtstraffer vorne links / Reversible Belt Tensioner Front Left
    14 x provide port:
      P_Awake_Diag_Actv_RBTM_FL_ST3: nonqueued-sender-com-spec{data-element=Awake_Diag_Actv_RBTM_FL_ST3, init-value=constant-reference=XDIS_h5tcyk98kzbgrc5svasomeyt}, provided-interface=IF_Awake_Diag_Actv_RBTM_FL_ST3  # Wachhalten für Diagnose aktiv / Stay awake for diagnostics active
      P_Awake_Ignition_On_RBTM_FL_ST3: nonqueued-sender-com-spec{data-element=Awake_Ignition_On_RBTM_FL_ST3, init-value=constant-reference=XDIS_h5tcyk98kzbgrc5svasomeyt}, provided-interface=IF_Awake_Ignition_On_RBTM_FL_ST3  # Wachhalten für Zündung eingeschaltet / Stay awake for ignition on
      P_Awake_NwStart_RBTM_FL_ST3: nonqueued-sender-com-spec{data-element=Awake_NwStart_RBTM_FL_ST3, init-value=constant-reference=XDIS_h5tcyk98kzbgrc5svasomeyt}, provided-interface=IF_Awake_NwStart_RBTM_FL_ST3  # Wachhalten für Netzwerkstartphase / Stay awake for network startup
      P_BltSlckDec_Md_XX_Stat_ST3: nonqueued-sender-com-spec{data-element=BltSlckDec_Md_XX_Stat_ST3, init-value=constant-reference=XDIS_1vei4uht6zuq0e57z2qtds6y7}, provided-interface=IF_BltSlckDec_Md_XX_Stat_ST3  # Modus Gurtlosereduktion Status / Belt slack decreasing mode state
      P_Develop8_Rs_RBTM_FL_ST3: nonqueued-sender-com-spec{data-element=Develop8_Rs_RBTM_FL_ST3, init-value=constant-reference=XDIS_dx2vtxvh1csnm7x2o8c32o294}, provided-interface=IG_Develop8_Rs_RBTM_FL_ST3_25obewk81wuyc38kk70ol6f0x  # Development Response (degraded)
      P_ECU_Id_RBTM_FL_ST3: nonqueued-sender-com-spec{data-element=ECU_Id_RBTM_FL_ST3, init-value=constant-reference=XDIS_69x5rmbg27ofsxv5i93olbdcr}, provided-interface=IF_ECU_Id_RBTM_FL_ST3  # ECU-Identifizierungsnummer / ECU identifier
      P_Meas_RBTM_FL_ST3: nonqueued-sender-com-spec{data-element=Meas8_RBTM_FL_ST3, init-value=constant-reference=XDIS_ckvw3q385offj9s5jhb6jp6cr}, provided-interface=IG_Meas8_RBTM_FL_ST3_dcsffxmk4lebax14ae8jyr2nd  # Messbotschaft (degraded) / Measurement (degraded)
      P_PS_Curve_FL_Stat_ST3: nonqueued-sender-com-spec{data-element=PS_Curve_FL_Stat_ST3, init-value=constant-reference=XDIS_avyye5ls1y4c08a0jv466vs3h}, provided-interface=IF_PS_Curve_FL_Stat_ST3  # PreSafe Curve Status vorne links / PreSafe Curve mode state front left
      P_RBTM_FL_Disp_Rq_ST3: nonqueued-sender-com-spec{data-element=RBTM_FL_Disp_Rq_ST3, init-value=constant-reference=XDIS_cy54nb3vm043oo6et4rw4sxxi}, provided-interface=IF_RBTM_FL_Disp_Rq_ST3  # Presafe Kombimeldung vorne links anzeigen / Presafe display request front left
      P_RBTM_FL_Tgl_ST3: nonqueued-sender-com-spec{data-element=RBTM_FL_Tgl_ST3, init-value=constant-reference=XDIS_h5tcyk98kzbgrc5svasomeyt}, provided-interface=IF_RBTM_FL_Tgl_ST3  # Presafe Togglebit
      P_RevBltTns_FL_ComCyc_Actv_ST3: nonqueued-sender-com-spec{data-element=RevBltTns_FL_ComCyc_Actv_ST3, init-value=constant-reference=XDIS_f4mtuwvd3r353o80f6rps7w7}, provided-interface=IF_RevBltTns_FL_ComCyc_Actv_ST3  # Reversibler Gurtstraffer vorne links Komfort-Straffzyklus aktiv / Reversible belt tensioner front left comfort tensioning cycle active
      P_RevBltTns_FL_SafeCyc_Actv_ST3: nonqueued-sender-com-spec{data-element=RevBltTns_FL_SafeCyc_Actv_ST3, init-value=constant-reference=XDIS_f4mtuwvd3r353o80f6rps7w7}, provided-interface=IF_RevBltTns_FL_SafeCyc_Actv_ST3  # Reversibler Gurtstraffer vorne links Sicherheits-Straffzyklus aktiv / Reversible belt tensioner front left safety tensioning cycle active
      P_ROE: nonqueued-sender-com-spec{data-element=ROE_XX_ST3, init-value=constant-reference=XDIS_95xfwhvar8lzg9cdzofn4oooa}, provided-interface=IG_ROE_XX_ST3_4ewk6hdthg4k2abg4vkvktubw  # Ereignis-Antwort (degraded) / Response on Event (degraded)
      P_WakeupRsn_RBTM_FL_ST3: nonqueued-sender-com-spec{data-element=WakeupRsn_RBTM_FL_ST3, init-value=constant-reference=XDIS_3jaoqj7gfnekl0vo7yq70x2ub}, provided-interface=IF_WakeupRsn_RBTM_FL_ST3  # Weckgrund / Wakeup reason
    36 x require port:
      R_ADAS_Meta_ST3: nonqueued-receiver-com-spec{data-element=ADAS_Meta_ST3, reception-props=timeout=10.1, alive-timeout=10.1, init-value=constant-reference=XDIS_e0ppmab9qlp72wzp0n595ikyr}, required-interface=IG_ADAS_Meta_ST3_5t037gwmf9dl2hvml0jpnv9dy  # ADAS Metadaten (degraded) / ADAS meta data (degraded)
      R_ADAS_Posn_ST3: nonqueued-receiver-com-spec{data-element=ADAS_Posn_ST3, reception-props=timeout=5.1, alive-timeout=5.1, init-value=constant-reference=XDIS_12iby7nm3kigcbaip97m7b94m}, required-interface=IG_ADAS_Posn_ST3_7s6pzau51nozrnxlccvr1dqvq  # ADAS Position (degraded)
      R_ADAS_Prediction_MsgTyp_ST3: nonqueued-receiver-com-spec{data-element=ADAS_Prediction_MsgTyp_ST3, reception-props=timeout=0, init-value=constant-reference=XDIS_2a2yz5m526fyufrfge0jdvur9}, required-interface=IF_ADAS_Prediction_MsgTyp_ST3  # ADAS Prediction: Message Type
      R_ADAS_Profile_Short_CurvLn_ST3: nonqueued-receiver-com-spec{data-element=ADAS_Profile_Short_CurvLn_ST3, reception-props=timeout=1.1, alive-timeout=1.1, init-value=constant-reference=XDIS_5q6kecggtt6ixzqit96uyqmo3}, required-interface=IG_ADAS_Profile_Short_CurvLn_ST3_81w1wno7bbxberhwp2jcfr8tz  # ADAS Kurzcharakteristik Curvature Linear (degraded) / ADAS short profile Curvature Linear (degraded)
      R_ADAS_ProfShort_ProfTyp_ST3: nonqueued-receiver-com-spec{data-element=ADAS_ProfShort_ProfTyp_ST3, reception-props=timeout=0, init-value=constant-reference=XDIS_5tr223jg6fys3d0tv4s093nze}, required-interface=IF_ADAS_ProfShort_ProfTyp_ST3  # Profile Short Message: Profiltyp / Profile Short Message: Profile Type
      R_Bckl_Sw_Fx_Stat_Pr5_ST3: nonqueued-receiver-com-spec{data-element=Bckl_Sw_Fx_Stat_Pr5_ST3, reception-props=timeout=1.1, end-to-end-transformation-com-spec-props{disable-end-to-end-check=false, max-delta-counter=3, max-error-state-init=0, max-error-state-invalid=0, max-error-state-valid=0, min-ok-state-init=1, min-ok-state-invalid=1, min-ok-state-valid=1, window-size-init=10, window-size-invalid=10, window-size-valid=10}, alive-timeout=1.1, init-value=constant-reference=XDIS_by5k2ulzqy4hav7734lki195k}, required-interface=IG_Bckl_Sw_Fx_Stat_Pr5_ST3_6ckxfn8j26ez9slws8s7zuact  # Bckl Sw Fx Status ST3 (degraded) / Bckl Sw Fx state ST3 (degraded)
      R_BeltHdOvr_XX_Stat_ST3: nonqueued-receiver-com-spec{data-element=BeltHdOvr_XX_Stat_ST3, reception-props=timeout=5.25, alive-timeout=5.25, init-value=constant-reference=XDIS_9pu33xhskzhvc3a6idhpuk7uh}, required-interface=IF_BeltHdOvr_XX_Stat_ST3  # Status Gurtbringer / Belt hand over state
      R_BltSlckDec_Md_Rq_HU_ST3: nonqueued-receiver-com-spec{data-element=BltSlckDec_Md_Rq_HU_ST3, reception-props=timeout=60.5, alive-timeout=60.5, init-value=constant-reference=XDIS_1vei4uht6zuq0e57z2qtds6y7}, required-interface=IF_BltSlckDec_Md_Rq_HU_ST3  # Anforderung Modus Gurtlosereduktion von Headunit / Belt slack decreasing mode request from Head Unit
      R_CLkS_DrRltch_Stat_Pr5_ST3: nonqueued-receiver-com-spec{data-element=CLkS_DrRltch_Stat_Pr5_ST3, reception-props=timeout=0, end-to-end-transformation-com-spec-props=disable-end-to-end-check=true, init-value=constant-reference=XDIS_2cviwteq6sdkb41vg3juq8qm5}, required-interface=IG_CLkS_DrRltch_Stat_Pr5_ST3_9cjfjqoxzg8myue62zdg7b3ws  # Zentralverriegelung Status Drehfalle Türen (degraded) / Central Locking System Rotary latch doors state (degraded)
      R_Develop8_Rq_RBTM_FL_ST3: nonqueued-receiver-com-spec{data-element=Develop8_Rq_RBTM_FL_ST3, reception-props=timeout=0, init-value=constant-reference=XDIS_1uf4istgprs3hvvzjvjv3yns0}, required-interface=IG_Develop8_Rq_RBTM_FL_ST3_38ed4c8igp8xxzbei3a6bgrm1  # Development Request (degraded)
      R_DI_Odo_Pr5_ST3: nonqueued-receiver-com-spec{data-element=DI_Odo_Pr5_ST3, reception-props=timeout=0, end-to-end-transformation-com-spec-props=disable-end-to-end-check=true, init-value=constant-reference=XDIS_8ty18e89uj9dq1u10d39n5ao8}, required-interface=IG_DI_Odo_Pr5_ST3_dqmkbik4b90gceqe8t96kp3yd  # DriverInformation Odometer (degraded)
      R_DidA_ExtTest_Pres_ST3: nonqueued-receiver-com-spec{data-element=DidA_ExtTest_Pres_ST3, reception-props=timeout=0, init-value=constant-reference=XDIS_f4mtuwvd3r353o80f6rps7w7}, required-interface=IF_DidA_ExtTest_Pres_ST3  # DidA Externer Tester erkannt / DidA external tester present
      R_DPC_Md_Rq_ESP_Pr5_ST3: nonqueued-receiver-com-spec{data-element=DPC_Md_Rq_ESP_Pr5_ST3, reception-props=timeout=0, end-to-end-transformation-com-spec-props=disable-end-to-end-check=true, init-value=constant-reference=XDIS_1k0wiwna366gg0qdmxvrmtw5q}, required-interface=IG_DPC_Md_Rq_ESP_Pr5_ST3_f0hx0tjzowsztgrknro9jwuwh  # Dynamic select Anforderung Pr 5 ST3 (degraded) / Dynamic select request Pr 5 ST3 (degraded)
      R_ELC_Lvr_Stat_Pr5_ST3: nonqueued-receiver-com-spec{data-element=ELC_Lvr_Stat_Pr5_ST3, reception-props=timeout=1.1, end-to-end-transformation-com-spec-props=disable-end-to-end-check=true, alive-timeout=1.1, init-value=constant-reference=XDIS_6wuj3k3qgtyyc049tu8amprma}, required-interface=IG_ELC_Lvr_Stat_Pr5_ST3_7k1u3p95ebi3423irpcsvtgpy  # Status Bedienhebel Außenlicht (degraded) / Exterior light lever state (degraded)
      R_EVC_CfgList_01_08_Pr5_ST3: nonqueued-receiver-com-spec{data-element=EVC_CfgList_01_08_Pr5_ST3, reception-props=timeout=2.5, end-to-end-transformation-com-spec-props=disable-end-to-end-check=true, alive-timeout=2.5, init-value=constant-reference=XDIS_7tqm5jy9oba0thvws62i3l28n}, required-interface=IG_EVC_CfgList_01_08_Pr5_ST3_40zxqtxkwyhasb66rr3qexjf2  # EVC Cfg List 01 08 Pr 5 ST3 (degraded)
      R_Ign_Stat_Pr5_ST3: nonqueued-receiver-com-spec{data-element=Ign_Stat_Pr5_ST3, reception-props=timeout=1.05, end-to-end-transformation-com-spec-props{disable-end-to-end-check=false, max-delta-counter=3, max-error-state-init=0, max-error-state-invalid=0, max-error-state-valid=0, min-ok-state-init=1, min-ok-state-invalid=1, min-ok-state-valid=1, window-size-init=10, window-size-invalid=10, window-size-valid=10}, alive-timeout=1.05, init-value=constant-reference=XDIS_8ptnmozvvqneybwnb1dteqblf}, required-interface=IG_Ign_Stat_Pr5_ST3_46s203zrl2qg54zbkbmirlx2b  # Zuendungsstatus (degraded) / Ignition state (degraded)
      R_Navi_RouteGuidance_Stat_ST3: nonqueued-receiver-com-spec{data-element=Navi_RouteGuidance_Stat_ST3, reception-props=timeout=10.1, alive-timeout=10.1, init-value=constant-reference=XDIS_edxyn89atnnz30urbv61ma706}, required-interface=IF_Navi_RouteGuidance_Stat_ST3  # Navigation Status Zielführung / Navigation route guidance state
      R_ORC_Impact2_Pr5_ST3: nonqueued-receiver-com-spec{data-element=ORC_Impact2_Pr5_ST3, reception-props=timeout=0, end-to-end-transformation-com-spec-props=disable-end-to-end-check=true, init-value=constant-reference=XDIS_6l5b88fcuqpu2imoz1fzls07a}, required-interface=IG_ORC_Impact2_Pr5_ST3_9ccpksmbwqz15ty9t9jr7ps1e  # ORC Impact 2 ST3 (degraded)
      R_ORC_Impact3_Pr5_ST3: nonqueued-receiver-com-spec{data-element=ORC_Impact3_Pr5_ST3, reception-props=timeout=0, end-to-end-transformation-com-spec-props{disable-end-to-end-check=false, max-delta-counter=3, max-error-state-init=0, max-error-state-invalid=0, max-error-state-valid=0, min-ok-state-init=1, min-ok-state-invalid=1, min-ok-state-valid=1, window-size-init=10, window-size-invalid=10, window-size-valid=10}, init-value=constant-reference=XDIS_c1pv78wydh7xh2ji5cbkvskd}, required-interface=IG_ORC_Impact3_Pr5_ST3_35qgq57bw73eamvx4gelk7iiv  # ORC Impact 3 ST3 (degraded)
      R_PN14_DDP_Sw_Stat_ST3: nonqueued-receiver-com-spec{data-element=PN14_DDP_Sw_Stat_ST3, reception-props=timeout=0, init-value=constant-reference=XDIS_c8apwmaohcx1gxigvciebloy2}, required-interface=IF_PN14_DDP_Sw_Stat_ST3  # Schalterstatus Tiefentladeschutz / Deep discharge protection switch state
      R_PN14_ProdMd_Stat_ST3: nonqueued-receiver-com-spec{data-element=PN14_ProdMd_Stat_ST3, reception-props=timeout=0, init-value=constant-reference=XDIS_4um78o9kgep1cp3dhn51ycc2o}, required-interface=IF_PN14_ProdMd_Stat_ST3  # Status des Bordnetz Produktionsmodus / Powernet production mode state
      R_PN14_SupBat_Volt_ST3: nonqueued-receiver-com-spec{data-element=PN14_SupBat_Volt_ST3, reception-props=timeout=0, init-value=constant-reference=XDIS_9jzhpgyeg4j2n16k3jmfeesjo}, required-interface=IF_PN14_SupBat_Volt_ST3  # Versorgungsbatterie Istspannung / Supply battery voltage
      R_PN14_TransMd_Stat_ST3: nonqueued-receiver-com-spec{data-element=PN14_TransMd_Stat_ST3, reception-props=timeout=0, init-value=constant-reference=XDIS_18rb2bxx4r5d75figzrcw50gp}, required-interface=IF_PN14_TransMd_Stat_ST3  # Bordnetz Status Transportmodus / Powernet transport mode status
      R_PresfAct_Adj_Pr5_ST3: nonqueued-receiver-com-spec{data-element=PresfAct_Adj_Pr5_ST3, reception-props=timeout=2.1, end-to-end-transformation-com-spec-props{disable-end-to-end-check=false, max-delta-counter=3, max-error-state-init=0, max-error-state-invalid=0, max-error-state-valid=0, min-ok-state-init=1, min-ok-state-invalid=1, min-ok-state-valid=1, window-size-init=10, window-size-invalid=10, window-size-valid=10}, alive-timeout=2.1, init-value=constant-reference=XDIS_1lex2znuqx5p6s5yy1dyffpdg}, required-interface=IG_PresfAct_Adj_Pr5_ST3_863uuptg5wch3t7i31c8crpa2  # Presf Aktor Steuerung ST3 (degraded) / Presf Actuator adjustment ST3 (degraded)
      R_PS_Curve_FL_Rq_HU_ST3: nonqueued-receiver-com-spec{data-element=PS_Curve_FL_Rq_HU_ST3, reception-props=timeout=10.1, alive-timeout=10.1, init-value=constant-reference=XDIS_avyye5ls1y4c08a0jv466vs3h}, required-interface=IF_PS_Curve_FL_Rq_HU_ST3  # Anforderung PreSafe Curve Modus von Headunit vorne links / PreSafe Curve mode request from headunit front left
      R_PT4_PTCoor4_Pr5_ST3: nonqueued-receiver-com-spec{data-element=PT4_PTCoor4_Pr5_ST3, reception-props=timeout=1.05, end-to-end-transformation-com-spec-props=disable-end-to-end-check=true, alive-timeout=1.05, init-value=constant-reference=XDIS_9h6oqehaueepowg2tijus0mir}, required-interface=IG_PT4_PTCoor4_Pr5_ST3_3rxtipq9xm5agzf69e8usehmj  # PT4_PTCoor4_Pr5_ST3 (degraded)
      R_PT4_PTCoor9_Pr5_ST3: nonqueued-receiver-com-spec{data-element=PT4_PTCoor9_Pr5_ST3, reception-props=timeout=5.1, end-to-end-transformation-com-spec-props=disable-end-to-end-check=true, alive-timeout=5.1, init-value=constant-reference=XDIS_4ns7wihv1xzpelli7hay25trg}, required-interface=IG_PT4_PTCoor9_Pr5_ST3_a7spavm295u68551d0tj6tl4v  # PT4 PT Coor 9 Pr 5 ST3 (degraded)
      R_PT4_PTCoor_DrvPosn_Gear_Pr5_ST3: nonqueued-receiver-com-spec{data-element=PT4_PTCoor_DrvPosn_Gear_Pr5_ST3, reception-props=timeout=0, end-to-end-transformation-com-spec-props=disable-end-to-end-check=true, init-value=constant-reference=XDIS_8ocy3iwo1ditemd6qwphg7b7i}, required-interface=IG_PT4_PTCoor_DrvPosn_Gear_Pr5_ST3_c8lirmw9wm5odas0h648yyd4w  # PT4 PT Coor Drv Position Gear Pr 5 ST3 (degraded) / PT4 PT Coor Drv position Gear Pr 5 ST3 (degraded)
      R_RevBltTns_FR_ComCyc_Actv_ST3: nonqueued-receiver-com-spec{data-element=RevBltTns_FR_ComCyc_Actv_ST3, reception-props=timeout=0, init-value=constant-reference=XDIS_f4mtuwvd3r353o80f6rps7w7}, required-interface=IF_RevBltTns_FR_ComCyc_Actv_ST3  # Reversibler Gurtstraffer vorne rechts Komfort-Straffzyklus aktiv / Reversible belt tensioner front right comfort tensioning cycle active
      R_RevBltTns_FR_SafeCyc_Actv_ST3: nonqueued-receiver-com-spec{data-element=RevBltTns_FR_SafeCyc_Actv_ST3, reception-props=timeout=0, init-value=constant-reference=XDIS_f4mtuwvd3r353o80f6rps7w7}, required-interface=IF_RevBltTns_FR_SafeCyc_Actv_ST3  # Reversibler Gurtstraffer vorne rechts Sicherheits-Straffzyklus aktiv / Reversible belt tensioner front right safety tensioning cycle active
      R_VehSpd_Disp_ST3: nonqueued-receiver-com-spec{data-element=VehSpd_Disp_ST3, reception-props=timeout=10.5, alive-timeout=10.5, init-value=constant-reference=XDIS_5khg03e556s88aodw5p7cozx4}, required-interface=IF_VehSpd_Disp_ST3  # Angezeigte Geschwindigkeit (ohne Zeigerdämpfung) / Displayed vehicle speed (without attenuation)
      R_VSS_TP_Auth_ST3: nonqueued-receiver-com-spec{data-element=VSS_TP_Auth_ST3, reception-props=timeout=0, init-value=constant-reference=XDIS_12zcafvpuxi1hcqhklsbnv4pg}, required-interface=IG_VSS_TP_Auth_ST3  # VSS-Transportprotokoll für Authentifizierung / Vehicle Security System Transport Protocol for authentication broadcast
      R_VSS_TP_RealTmOffset_ST3: nonqueued-receiver-com-spec{data-element=VSS_TP_RealTmOffset_ST3, reception-props=timeout=0, init-value=constant-reference=XDIS_12zcafvpuxi1hcqhklsbnv4pg}, required-interface=IG_VSS_TP_RealTmOffset_ST3  # VSS-Transportprotokoll für Echtzeit-Offset / Vehicle Security System Transport Protocol for real time offset broadcast
      R_VSS_TP_SecTickCount_ST3: nonqueued-receiver-com-spec{data-element=VSS_TP_SecTickCount_ST3, reception-props=timeout=0, init-value=constant-reference=XDIS_12zcafvpuxi1hcqhklsbnv4pg}, required-interface=IG_VSS_TP_SecTickCount_ST3  # VSS-Transportprotokoll für sichere Zeit / Vehicle Security System Transport Protocol for secure tick count
      R_VSS_TP_SharedSecret_ST3: nonqueued-receiver-com-spec{data-element=VSS_TP_SharedSecret_ST3, reception-props=timeout=0, init-value=constant-reference=XDIS_12zcafvpuxi1hcqhklsbnv4pg}, required-interface=IG_VSS_TP_SharedSecret_ST3  # VSS-Transportprotokoll für gemeinsames Geheimnis / Vehicle Security System Transport Protocol for shared secret broadcast
      R_VSS_TP_VIN_ST3: nonqueued-receiver-com-spec{data-element=VSS_TP_VIN_ST3, reception-props=timeout=0, init-value=constant-reference=XDIS_3jcrrl3ll1e4yr6lszlogfin7}, required-interface=IG_VSS_TP_VIN_ST3  # VSS-Transportprotokoll für Fahrzeugidentifikationsnummer / Vehicle Security System Transport Protocol for Vehicle Identification Number
    14 x provide port:
      ICS_VIN_Ctrl_ST3: provided-com-specs=[{operation=Set, queue-length=1}, {operation=Lock, queue-length=1}], provided-interface=ICS_VIN_Ctrl_ST3
      ICS_VIN_ST3: server-com-spec{operation=Get, queue-length=1}, provided-interface=ICS_VIN_ST3
      P_Awake_Diag_Actv_RBTM_FR_ST3: nonqueued-sender-com-spec{data-element=Awake_Diag_Actv_RBTM_FR_ST3, init-value=constant-reference=XDIS_h5tcyk98kzbgrc5svasomeyt}, provided-interface=IF_Awake_Diag_Actv_RBTM_FR_ST3  # Wachhalten für Diagnose aktiv / Stay awake for diagnostics active
      P_Awake_Ignition_On_RBTM_FR_ST3: nonqueued-sender-com-spec{data-element=Awake_Ignition_On_RBTM_FR_ST3, init-value=constant-reference=XDIS_h5tcyk98kzbgrc5svasomeyt}, provided-interface=IF_Awake_Ignition_On_RBTM_FR_ST3  # Wachhalten für Zündung eingeschaltet / Stay awake for ignition on
      P_Awake_NwStart_RBTM_FR_ST3: nonqueued-sender-com-spec{data-element=Awake_NwStart_RBTM_FR_ST3, init-value=constant-reference=XDIS_h5tcyk98kzbgrc5svasomeyt}, provided-interface=IF_Awake_NwStart_RBTM_FR_ST3  # Wachhalten für Netzwerkstartphase / Stay awake for network startup
      P_Develop8_Rs_RBTM_FR_ST3: nonqueued-sender-com-spec{data-element=Develop8_Rs_RBTM_FR_ST3, init-value=constant-reference=XDIS_7ll3jj0kzg4pxwvhz4t7z1xms}, provided-interface=IG_Develop8_Rs_RBTM_FR_ST3_1bgznsxvbko9nyo78yin9nalx  # Development Response (degraded)
      P_ECU_Id_RBTM_FR_ST3: nonqueued-sender-com-spec{data-element=ECU_Id_RBTM_FR_ST3, init-value=constant-reference=XDIS_2f2k10or7fzjcnsiqkruf2jdj}, provided-interface=IF_ECU_Id_RBTM_FR_ST3  # ECU-Identifizierungsnummer / ECU identifier
      P_Meas_RBTM_FR_ST3: nonqueued-sender-com-spec{data-element=Meas8_RBTM_FR_ST3, init-value=constant-reference=XDIS_byyw7b3ki3w79jkgp9jr5allr}, provided-interface=IG_Meas8_RBTM_FR_ST3_3bo6gxw4jc1o7t5aoxk3awdcy  # Messbotschaft (degraded) / Measurement (degraded)
      P_PS_Curve_FR_Stat_ST3: nonqueued-sender-com-spec{data-element=PS_Curve_FR_Stat_ST3, init-value=constant-reference=XDIS_avyye5ls1y4c08a0jv466vs3h}, provided-interface=IF_PS_Curve_FR_Stat_ST3  # PreSafe Curve Status vorne rechts / PreSafe Curve mode state front right
      P_RBTM_FR_Disp_Rq_ST3: nonqueued-sender-com-spec{data-element=RBTM_FR_Disp_Rq_ST3, init-value=constant-reference=XDIS_cy54nb3vm043oo6et4rw4sxxi}, provided-interface=IF_RBTM_FR_Disp_Rq_ST3  # Presafe Kombimeldung vorne rechts anzeigen / Presafe display request front right
      P_RBTM_FR_Tgl_ST3: nonqueued-sender-com-spec{data-element=RBTM_FR_Tgl_ST3, init-value=constant-reference=XDIS_h5tcyk98kzbgrc5svasomeyt}, provided-interface=IF_RBTM_FR_Tgl_ST3  # Presafe Togglebit
      P_RevBltTns_FR_ComCyc_Actv_ST3: nonqueued-sender-com-spec{data-element=RevBltTns_FR_ComCyc_Actv_ST3, init-value=constant-reference=XDIS_f4mtuwvd3r353o80f6rps7w7}, provided-interface=IF_RevBltTns_FR_ComCyc_Actv_ST3_001  # Reversibler Gurtstraffer vorne rechts Komfort-Straffzyklus aktiv / Reversible belt tensioner front right comfort tensioning cycle active
      P_RevBltTns_FR_SafeCyc_Actv_ST3: nonqueued-sender-com-spec{data-element=RevBltTns_FR_SafeCyc_Actv_ST3, init-value=constant-reference=XDIS_f4mtuwvd3r353o80f6rps7w7}, provided-interface=IF_RevBltTns_FR_SafeCyc_Actv_ST3_001  # Reversibler Gurtstraffer vorne rechts Sicherheits-Straffzyklus aktiv / Reversible belt tensioner front right safety tensioning cycle active
      P_WakeupRsn_RBTM_FR_ST3: nonqueued-sender-com-spec{data-element=WakeupRsn_RBTM_FR_ST3, init-value=constant-reference=XDIS_3jaoqj7gfnekl0vo7yq70x2ub}, provided-interface=IF_WakeupRsn_RBTM_FR_ST3  # Weckgrund / Wakeup reason
    4 x require port:
      R_Develop8_Rq_RBTM_FR_ST3: nonqueued-receiver-com-spec{data-element=Develop8_Rq_RBTM_FR_ST3, reception-props=timeout=0, init-value=constant-reference=XDIS_6efbipe0xf9n4p1rmexr8mnnj}, required-interface=IG_Develop8_Rq_RBTM_FR_ST3_972r28igpapvdp6ireogwrkb1  # Development Request (degraded)
      R_PS_Curve_FR_Rq_HU_ST3: nonqueued-receiver-com-spec{data-element=PS_Curve_FR_Rq_HU_ST3, reception-props=timeout=10.1, alive-timeout=10.1, init-value=constant-reference=XDIS_avyye5ls1y4c08a0jv466vs3h}, required-interface=IF_PS_Curve_FR_Rq_HU_ST3  # IF PS Curve vorne rechts Anforderung HU ST3 / IF PS Curve front right Request(ed) HU ST3
      R_RevBltTns_FL_ComCyc_Actv_ST3: nonqueued-receiver-com-spec{data-element=RevBltTns_FL_ComCyc_Actv_ST3, reception-props=timeout=0, init-value=constant-reference=XDIS_f4mtuwvd3r353o80f6rps7w7}, required-interface=IF_RevBltTns_FL_ComCyc_Actv_ST3_001  # Reversibler Gurtstraffer vorne links Komfort-Straffzyklus aktiv / Reversible belt tensioner front left comfort tensioning cycle active
      R_RevBltTns_FL_SafeCyc_Actv_ST3: nonqueued-receiver-com-spec{data-element=RevBltTns_FL_SafeCyc_Actv_ST3, reception-props=timeout=0, init-value=constant-reference=XDIS_f4mtuwvd3r353o80f6rps7w7}, required-interface=IF_RevBltTns_FL_SafeCyc_Actv_ST3_001  # Reversibler Gurtstraffer vorne links Sicherheits-Straffzyklus aktiv / Reversible belt tensioner front left safety tensioning cycle active
    4 x provide port:
      P_VSS_TP_SecTickCount_ST3: nonqueued-sender-com-spec{data-element=VSS_TP_SecTickCount_ST3, init-value=constant-reference=XDIS_12zcafvpuxi1hcqhklsbnv4pg}, provided-interface=IG_VSS_TP_SecTickCount_ST3
      P_RBTMFL_Actv_Lvl_ST35: nonqueued-sender-com-spec{data-element=RBTMFL_Actv_Lvl_ST35, init-value=constant-reference=XDIS_chxf7btms1nmfvn0rkw64k08e}, provided-interface=IF_RBTMFL_Actv_Lvl_ST35  # aktives Straffprofil vorne links / active seatbelt tensioning profile front left
      P_RBTMFL_SP_ActvClient_ST35: nonqueued-sender-com-spec{data-element=RBTMFL_SP_ActvClient_ST35, init-value=constant-reference=XDIS_ech1daxmjqjqyzrsfliduv3re}, provided-interface=IF_RBTMFL_SP_ActvClient_ST35  # Anforderungsquelle aktive Gurtstraffung vorne links / Active seatbelt tensioning request source front left
      P_RBTMFL_SP_FctPrecond_Stat_ST35: nonqueued-sender-com-spec{data-element=RBTMFL_SP_FctPrecond_Stat_ST35, init-value=constant-reference=XDIS_ax33oucaqs87guek1p0j7vyqa}, provided-interface=IF_RBTMFL_SP_FctPrecond_Stat_ST35  # Nicht erfüllten Funktionsbedingungen für rev. Gurtstraffung vorne links / List of unfulfilled preconditions for rev. seatbelt tensioning front left
    require port R_SBeltTens_SP_Lvl_Pr5_ST3: nonqueued-receiver-com-spec{data-element=SBeltTens_SP_Lvl_Pr5_ST3, reception-props=timeout=2, end-to-end-transformation-com-spec-props{disable-end-to-end-check=false, max-delta-counter=3, max-error-state-init=0, max-error-state-invalid=0, max-error-state-valid=0, min-ok-state-init=1, min-ok-state-invalid=1, min-ok-state-valid=1, window-size-init=10, window-size-invalid=10, window-size-valid=10}, alive-timeout=2, init-value=constant-reference=XDIS_4wiqeqoz18rz4k73xcp12oii1}, required-interface=IG_SBeltTens_SP_Lvl_Pr5_ST3_aljrkz9re372o0jtum2i5lh8w  # Seat Belt Tensioner SP Lvl ST3 (degraded)
    provide port P_RBTMFR_Actv_Lvl_ST35: nonqueued-sender-com-spec{data-element=RBTMFR_Actv_Lvl_ST35, init-value=constant-reference=XDIS_chxf7btms1nmfvn0rkw64k08e}, provided-interface=IF_RBTMFR_Actv_Lvl_ST35  # aktives Straffprofil vorne rechts / active seatbelt tensioning profile front right
    provide port P_RBTMFR_SP_ActvClient_ST35: nonqueued-sender-com-spec{data-element=RBTMFR_SP_ActvClient_ST35, init-value=constant-reference=XDIS_ech1daxmjqjqyzrsfliduv3re}, provided-interface=IF_RBTMFR_SP_ActvClient_ST35  # Anforderungsquelle aktive Gurtstraffung vorne rechts / Active seatbelt tensioning request source front right
    provide port P_RBTMFR_SP_FctPrecond_Stat_ST35: nonqueued-sender-com-spec{data-element=RBTMFR_SP_FctPrecond_Stat_ST35, init-value=constant-reference=XDIS_ax33oucaqs87guek1p0j7vyqa}, provided-interface=IF_RBTMFR_SP_FctPrecond_Stat_ST35  # Nicht erfüllten Funktionsbedingungen für rev. Gurtstraffung vorne rechts / List of unfulfilled preconditions for rev. seatbelt tensioning front right
    require port R_PN14_SupBat_Volt_ST3_1: nonqueued-receiver-com-spec{data-element=PN14_SupBat_Volt_ST3, init-value=constant-reference=XDIS_9jzhpgyeg4j2n16k3jmfeesjo}, required-interface=IF_PN14_SupBat_Volt_ST3  # Versorgungsbatterie Istspannung / Supply battery voltage
    require port R_PT4_PTCoor4_Pr5_ST3_1: nonqueued-receiver-com-spec{data-element=PT4_PTCoor4_Pr5_ST3, end-to-end-transformation-com-spec-props=disable-end-to-end-check=true, alive-timeout=1.05, init-value=constant-reference=XDIS_9h6oqehaueepowg2tijus0mir}, required-interface=IG_PT4_PTCoor4_Pr5_ST3_3rxtipq9xm5agzf69e8usehmj  # PT4_PTCoor4_Pr5_ST3 (degraded)
    require port R_PT4_PTCoor_DrvPosn_Gear_Pr5_ST3_1: nonqueued-receiver-com-spec{data-element=PT4_PTCoor_DrvPosn_Gear_Pr5_ST3, end-to-end-transformation-com-spec-props=disable-end-to-end-check=true, init-value=constant-reference=XDIS_8ocy3iwo1ditemd6qwphg7b7i}, required-interface=IG_PT4_PTCoor_DrvPosn_Gear_Pr5_ST3_c8lirmw9wm5odas0h648yyd4w  # PT4 PT Coor Drv Position Gear Pr 5 ST3 (degraded) / PT4 PT Coor Drv position Gear Pr 5 ST3 (degraded)
    10 x component:
      VSS_Slave_Lvl2_ST3: type=VSS_Slave_ST3  # Vehicle Security Slave
      SeatBeltComf_BeltAdj_FL_ST3: type=SeatBeltComf_BeltAdj_FL_ST3  # Gurtkomfort Gurtanpassung vorne links / Seat Belt Comfort Belt Adjustment Front Left
      Diagnostics_RBTM_FL_ST3: type=Diagnostics_RBTM_FL_ST3
      BaseFunction_ECU_RBTM_FL_ST3: type=BaseFunction_ECU_RBTM_FL_ST3  # Base Function
      PRESAFE_Function_Belt_Tensioner_Lt_ST3: type=PRESAFE_Function_Belt_Tensioner_Lt_ST3  # Ausführung der reversiblen Gurtsraffung mit Hilfe des Gurtes in Gefahrensituationen / execution of a reversible belt tensioning by belt in critical situations
      Autoliv: type=Autoliv
      PRESAFE_Function_Belt_Tensioner_Rt_ST3: type=PRESAFE_Function_Belt_Tensioner_Rt_ST3  # Ausführung der reversiblen Gurtsraffung mit Hilfe des Gurtes in Gefahrensituationen / execution of a reversible belt tensioning by belt in critical situations
      Diagnostics_RBTM_FR_ST3: type=Diagnostics_RBTM_FR_ST3
      SeatBeltComf_BeltAdj_FR_ST3: type=SeatBeltComf_BeltAdj_FR_ST3  # Gurtkomfort Gurtanpassung vorne rechts / Seat Belt Comfort Belt Adjustment Front Right
      BaseFunction_ECU_RBTM_FR_ST3: type=BaseFunction_ECU_RBTM_FR_ST3  # Base Function
    connect VSS_Slave_Lvl2_ST3.P_Sec_Event_ST3 -> Diagnostics_RBTM_FL_ST3.R_Sec_Event_ST3, variation-point=post-build-variant-condition{matching-criterion=SideAllocation, value=0}  # Assembly connector for P_Sec_Event_ST3 and R_Sec_Event_ST3
    delegate PRESAFE_Function_Belt_Tensioner_Lt_ST3.R_EVC_CfgList_01_08_Pr5_ST3 <-> outer port R_EVC_CfgList_01_08_Pr5_ST3  # Delegation connector for R_EVC_CfgList_01_08_Pr5_ST3 and R_EVC_CfgList_01_08_Pr5_ST3
    delegate BaseFunction_ECU_RBTM_FL_ST3.P_Awake_Ignition_On_RBTM_FL_ST3 <-> outer port P_Awake_Ignition_On_RBTM_FL_ST3  # Delegation connector for P_Awake_Ignition_On_RBTM_FL_ST3 and P_Awake_Ignition_On_RBTM_FL_ST3
    delegate PRESAFE_Function_Belt_Tensioner_Lt_ST3.P_RBTM_FL_Disp_Rq_ST3 <-> outer port P_RBTM_FL_Disp_Rq_ST3  # Delegation connector for P_RBTM_FL_Disp_Rq_ST3 and P_RBTM_FL_Disp_Rq_ST3
    delegate PRESAFE_Function_Belt_Tensioner_Lt_ST3.R_Ign_Stat_Pr5_ST3 <-> outer port R_Ign_Stat_Pr5_ST3  # Delegation connector for R_Ign_Stat_Pr5_ST3 and R_Ign_Stat_Pr5_ST3
    delegate PRESAFE_Function_Belt_Tensioner_Lt_ST3.R_Navi_RouteGuidance_Stat_ST3 <-> outer port R_Navi_RouteGuidance_Stat_ST3  # Delegation connector for R_Navi_RouteGuidance_Stat_ST3 and R_Navi_RouteGuidance_Stat_ST3
    delegate PRESAFE_Function_Belt_Tensioner_Lt_ST3.R_PS_Curve_FL_Rq_HU_ST3 <-> outer port R_PS_Curve_FL_Rq_HU_ST3  # Delegation connector for R_PS_Curve_FL_Rq_HU_ST3 and R_PS_Curve_FL_Rq_HU_ST3
    delegate PRESAFE_Function_Belt_Tensioner_Lt_ST3.R_ADAS_Prediction_MsgTyp_ST3 <-> outer port R_ADAS_Prediction_MsgTyp_ST3  # Delegation connector for R_ADAS_Prediction_MsgTyp_ST3 and R_ADAS_Prediction_MsgTyp_ST3
    delegate SeatBeltComf_BeltAdj_FL_ST3.R_PresfAct_Adj_Pr5_ST3 <-> outer port R_PresfAct_Adj_Pr5_ST3  # Delegation connector for R_PresfAct_Adj_Pr5_ST3 and R_PresfAct_Adj_Pr5_ST3
    delegate PRESAFE_Function_Belt_Tensioner_Lt_ST3.R_BeltHdOvr_XX_Stat_ST3 <-> outer port R_BeltHdOvr_XX_Stat_ST3  # Delegation connector for R_BeltHdOvr_XX_Stat_ST3 and R_BeltHdOvr_XX_Stat_ST3
    delegate Diagnostics_RBTM_FL_ST3.R_PN14_TransMd_Stat_ST3 <-> outer port R_PN14_TransMd_Stat_ST3  # Delegation connector for R_PN14_TransMd_Stat_ST3 and R_PN14_TransMd_Stat_ST3
    delegate SeatBeltComf_BeltAdj_FL_ST3.R_PN14_DDP_Sw_Stat_ST3 <-> outer port R_PN14_DDP_Sw_Stat_ST3  # Delegation connector for R_PN14_DDP_Sw_Stat_ST3 and R_PN14_DDP_Sw_Stat_ST3
    delegate Diagnostics_RBTM_FL_ST3.R_Ign_Stat_Pr5_ST3 <-> outer port R_Ign_Stat_Pr5_ST3  # Delegation connector for R_Ign_Stat_Pr5_ST3 and R_Ign_Stat_Pr5_ST3
    delegate SeatBeltComf_BeltAdj_FL_ST3.R_VehSpd_Disp_ST3 <-> outer port R_VehSpd_Disp_ST3  # Delegation connector for R_VehSpd_Disp_ST3 and R_VehSpd_Disp_ST3
    delegate PRESAFE_Function_Belt_Tensioner_Lt_ST3.R_ADAS_ProfShort_ProfTyp_ST3 <-> outer port R_ADAS_ProfShort_ProfTyp_ST3  # Delegation connector for R_ADAS_ProfShort_ProfTyp_ST3 and R_ADAS_ProfShort_ProfTyp_ST3
    delegate VSS_Slave_Lvl2_ST3.R_VSS_TP_Auth_ST3 <-> outer port R_VSS_TP_Auth_ST3  # Delegation connector for R_VSS_TP_Auth_ST3 and R_VSS_TP_Auth_ST3
    delegate Diagnostics_RBTM_FL_ST3.R_DI_Odo_Pr5_ST3 <-> outer port R_DI_Odo_Pr5_ST3  # Delegation connector for R_DI_Odo_Pr5_ST3 and R_DI_Odo_Pr5_ST3
    delegate PRESAFE_Function_Belt_Tensioner_Lt_ST3.R_RevBltTns_FR_SafeCyc_Actv_ST3 <-> outer port R_RevBltTns_FR_SafeCyc_Actv_ST3  # Delegation connector for R_RevBltTns_FR_SafeCyc_Actv_ST3 and R_RevBltTns_FR_SafeCyc_Actv_ST3
    delegate SeatBeltComf_BeltAdj_FL_ST3.P_RevBltTns_FL_ComCyc_Actv_ST3 <-> outer port P_RevBltTns_FL_ComCyc_Actv_ST3  # Delegation connector for P_RevBltTns_FL_ComCyc_Actv_ST3 and P_RevBltTns_FL_ComCyc_Actv_ST3
    delegate PRESAFE_Function_Belt_Tensioner_Lt_ST3.R_PresfAct_Adj_Pr5_ST3 <-> outer port R_PresfAct_Adj_Pr5_ST3  # Delegation connector for R_PresfAct_Adj_Pr5_ST3 and R_PresfAct_Adj_Pr5_ST3
    delegate SeatBeltComf_BeltAdj_FL_ST3.R_PT4_PTCoor_DrvPosn_Gear_Pr5_ST3 <-> outer port R_PT4_PTCoor_DrvPosn_Gear_Pr5_ST3  # Delegation connector for R_PT4_PTCoor_DrvPosn_Gear_Pr5_ST3 and R_PT4_PTCoor_DrvPosn_Gear_Pr5_ST3
    delegate Diagnostics_RBTM_FL_ST3.P_ROE <-> outer port P_ROE  # Delegation connector for P_ROE and P_ROE
    delegate SeatBeltComf_BeltAdj_FL_ST3.R_RevBltTns_FR_ComCyc_Actv_ST3 <-> outer port R_RevBltTns_FR_ComCyc_Actv_ST3  # Delegation connector for R_RevBltTns_FR_ComCyc_Actv_ST3 and R_RevBltTns_FR_ComCyc_Actv_ST3
    delegate Diagnostics_RBTM_FL_ST3.R_PN14_ProdMd_Stat_ST3 <-> outer port R_PN14_ProdMd_Stat_ST3  # Delegation connector for R_PN14_ProdMd_Stat_ST3 and R_PN14_ProdMd_Stat_ST3
    delegate VSS_Slave_Lvl2_ST3.R_VSS_TP_SharedSecret_ST3 <-> outer port R_VSS_TP_SharedSecret_ST3  # Delegation connector for R_VSS_TP_SharedSecret_ST3 and R_VSS_TP_SharedSecret_ST3
    delegate PRESAFE_Function_Belt_Tensioner_Lt_ST3.R_Bckl_Sw_Fx_Stat_Pr5_ST3 <-> outer port R_Bckl_Sw_Fx_Stat_Pr5_ST3  # Delegation connector for R_Bckl_Sw_Fx_Stat_Pr5_ST3 and R_Bckl_Sw_Fx_Stat_Pr5_ST3
    delegate PRESAFE_Function_Belt_Tensioner_Lt_ST3.P_RBTM_FL_Tgl_ST3 <-> outer port P_RBTM_FL_Tgl_ST3  # Delegation connector for P_RBTM_FL_Tgl_ST3 and P_RBTM_FL_Tgl_ST3
    delegate VSS_Slave_Lvl2_ST3.R_VSS_TP_SecTickCount_ST3 <-> outer port R_VSS_TP_SecTickCount_ST3  # Delegation connector for R_VSS_TP_SecTickCount_ST3 and R_VSS_TP_SecTickCount_ST3
    delegate BaseFunction_ECU_RBTM_FL_ST3.P_Meas_RBTM_FL_ST3 <-> outer port P_Meas_RBTM_FL_ST3  # Delegation connector for P_Meas_RBTM_FL_ST3 and P_Meas_RBTM_FL_ST3
    delegate SeatBeltComf_BeltAdj_FL_ST3.R_BltSlckDec_Md_Rq_HU_ST3 <-> outer port R_BltSlckDec_Md_Rq_HU_ST3  # Delegation connector for R_BltSlckDec_Md_Rq_HU_ST3 and R_BltSlckDec_Md_Rq_HU_ST3
    delegate BaseFunction_ECU_RBTM_FL_ST3.P_WakeupRsn_RBTM_FL_ST3 <-> outer port P_WakeupRsn_RBTM_FL_ST3  # Delegation connector for P_WakeupRsn_RBTM_FL_ST3 and P_WakeupRsn_RBTM_FL_ST3
    delegate PRESAFE_Function_Belt_Tensioner_Lt_ST3.R_ADAS_Profile_Short_CurvLn_ST3 <-> outer port R_ADAS_Profile_Short_CurvLn_ST3  # Delegation connector for R_ADAS_Profile_Short_CurvLn_ST3 and R_ADAS_Profile_Short_CurvLn_ST3
    delegate SeatBeltComf_BeltAdj_FL_ST3.R_PT4_PTCoor4_Pr5_ST3 <-> outer port R_PT4_PTCoor4_Pr5_ST3  # Delegation connector for R_PT4_PTCoor4_Pr5_ST3 and R_PT4_PTCoor4_Pr5_ST3
    delegate BaseFunction_ECU_RBTM_FL_ST3.P_ECU_Id_RBTM_FL_ST3 <-> outer port P_ECU_Id_RBTM_FL_ST3  # Delegation connector for P_ECU_Id_RBTM_FL_ST3 and P_ECU_Id_RBTM_FL_ST3
    delegate VSS_Slave_Lvl2_ST3.R_Ign_Stat_Pr5_ST3 <-> outer port R_Ign_Stat_Pr5_ST3  # Delegation connector for R_Ign_Stat_Pr5_ST3 and R_Ign_Stat_Pr5_ST3
    delegate SeatBeltComf_BeltAdj_FL_ST3.R_Bckl_Sw_Fx_Stat_Pr5_ST3 <-> outer port R_Bckl_Sw_Fx_Stat_Pr5_ST3  # Delegation connector for R_Bckl_Sw_Fx_Stat_Pr5_ST3 and R_Bckl_Sw_Fx_Stat_Pr5_ST3
    delegate BaseFunction_ECU_RBTM_FL_ST3.P_Awake_NwStart_RBTM_FL_ST3 <-> outer port P_Awake_NwStart_RBTM_FL_ST3  # Delegation connector for P_Awake_NwStart_RBTM_FL_ST3 and P_Awake_NwStart_RBTM_FL_ST3
    delegate BaseFunction_ECU_RBTM_FL_ST3.P_Develop8_Rs_RBTM_FL_ST3 <-> outer port P_Develop8_Rs_RBTM_FL_ST3  # Delegation connector for P_Develop8_Rs_RBTM_FL_ST3 and P_Develop8_Rs_RBTM_FL_ST3
    delegate PRESAFE_Function_Belt_Tensioner_Lt_ST3.P_PS_Curve_FL_Stat_ST3 <-> outer port P_PS_Curve_FL_Stat_ST3  # Delegation connector for P_PS_Curve_FL_Stat_ST3 and P_PS_Curve_FL_Stat_ST3
    delegate SeatBeltComf_BeltAdj_FL_ST3.R_ORC_Impact3_Pr5_ST3 <-> outer port R_ORC_Impact3_Pr5_ST3  # Delegation connector for R_ORC_Impact3_Pr5_ST3 and R_ORC_Impact3_Pr5_ST3
    delegate Diagnostics_RBTM_FL_ST3.R_PN14_SupBat_Volt_ST3 <-> outer port R_PN14_SupBat_Volt_ST3  # Delegation connector for R_PN14_SupBat_Volt_ST3 and R_PN14_SupBat_Volt_ST3
    delegate VSS_Slave_Lvl2_ST3.R_VSS_TP_RealTmOffset_ST3 <-> outer port R_VSS_TP_RealTmOffset_ST3  # Delegation connector for R_VSS_TP_RealTmOffset_ST3 and R_VSS_TP_RealTmOffset_ST3
    delegate BaseFunction_ECU_RBTM_FL_ST3.R_Develop8_Rq_RBTM_FL_ST3 <-> outer port R_Develop8_Rq_RBTM_FL_ST3  # Delegation connector for R_Develop8_Rq_RBTM_FL_ST3 and R_Develop8_Rq_RBTM_FL_ST3
    delegate PRESAFE_Function_Belt_Tensioner_Lt_ST3.R_ADAS_Meta_ST3 <-> outer port R_ADAS_Meta_ST3  # Delegation connector for R_ADAS_Meta_ST3 and R_ADAS_Meta_ST3
    delegate SeatBeltComf_BeltAdj_FL_ST3.R_CLkS_DrRltch_Stat_Pr5_ST3 <-> outer port R_CLkS_DrRltch_Stat_Pr5_ST3  # Delegation connector for R_CLkS_DrRltch_Stat_Pr5_ST3 and R_CLkS_DrRltch_Stat_Pr5_ST3
    delegate SeatBeltComf_BeltAdj_FL_ST3.R_ORC_Impact2_Pr5_ST3 <-> outer port R_ORC_Impact2_Pr5_ST3  # Delegation connector for R_ORC_Impact2_Pr5_ST3 and R_ORC_Impact2_Pr5_ST3
    delegate BaseFunction_ECU_RBTM_FL_ST3.P_Awake_Diag_Actv_RBTM_FL_ST3 <-> outer port P_Awake_Diag_Actv_RBTM_FL_ST3  # Delegation connector for P_Awake_Diag_Actv_RBTM_FL_ST3 and P_Awake_Diag_Actv_RBTM_FL_ST3
    delegate PRESAFE_Function_Belt_Tensioner_Lt_ST3.R_ORC_Impact3_Pr5_ST3 <-> outer port R_ORC_Impact3_Pr5_ST3  # Delegation connector for R_ORC_Impact3_Pr5_ST3 and R_ORC_Impact3_Pr5_ST3
    delegate SeatBeltComf_BeltAdj_FL_ST3.R_EVC_CfgList_01_08_Pr5_ST3 <-> outer port R_EVC_CfgList_01_08_Pr5_ST3  # Delegation connector for R_EVC_CfgList_01_08_Pr5_ST3 and R_EVC_CfgList_01_08_Pr5_ST3
    delegate PRESAFE_Function_Belt_Tensioner_Lt_ST3.R_ELC_Lvr_Stat_Pr5_ST3 <-> outer port R_ELC_Lvr_Stat_Pr5_ST3  # Delegation connector for R_ELC_Lvr_Stat_Pr5_ST3 and R_ELC_Lvr_Stat_Pr5_ST3
    delegate PRESAFE_Function_Belt_Tensioner_Lt_ST3.P_RevBltTns_FL_SafeCyc_Actv_ST3 <-> outer port P_RevBltTns_FL_SafeCyc_Actv_ST3  # Delegation connector for P_RevBltTns_FL_SafeCyc_Actv_ST3 and P_RevBltTns_FL_SafeCyc_Actv_ST3
    delegate Diagnostics_RBTM_FL_ST3.R_PT4_PTCoor4_Pr5_ST3 <-> outer port R_PT4_PTCoor4_Pr5_ST3  # Delegation connector for R_PT4_PTCoor4_Pr5_ST3 and R_PT4_PTCoor4_Pr5_ST3
    delegate VSS_Slave_Lvl2_ST3.R_VSS_TP_VIN_ST3 <-> outer port R_VSS_TP_VIN_ST3  # Delegation connector for R_VSS_TP_VIN_ST3 and R_VSS_TP_VIN_ST3
    delegate PRESAFE_Function_Belt_Tensioner_Lt_ST3.R_ADAS_Posn_ST3 <-> outer port R_ADAS_Posn_ST3  # Delegation connector for R_ADAS_Posn_ST3 and R_ADAS_Posn_ST3
    delegate SeatBeltComf_BeltAdj_FL_ST3.R_DPC_Md_Rq_ESP_Pr5_ST3 <-> outer port R_DPC_Md_Rq_ESP_Pr5_ST3  # Delegation connector for R_DPC_Md_Rq_ESP_Pr5_ST3 and R_DPC_Md_Rq_ESP_Pr5_ST3
    delegate Diagnostics_RBTM_FL_ST3.R_DidA_ExtTest_Pres_ST3 <-> outer port R_DidA_ExtTest_Pres_ST3  # Delegation connector for R_DidA_ExtTest_Pres_ST3 and R_DidA_ExtTest_Pres_ST3
    delegate SeatBeltComf_BeltAdj_FL_ST3.R_PT4_PTCoor9_Pr5_ST3 <-> outer port R_PT4_PTCoor9_Pr5_ST3  # Delegation connector for R_PT4_PTCoor9_Pr5_ST3 and R_PT4_PTCoor9_Pr5_ST3
    delegate VSS_Slave_Lvl2_ST3.R_DI_Odo_Pr5_ST3 <-> outer port R_DI_Odo_Pr5_ST3  # Delegation connector for R_DI_Odo_Pr5_ST3 and R_DI_Odo_Pr5_ST3
    delegate VSS_Slave_Lvl2_ST3.P_ICS_VIN_Ctrl_ST3 <-> outer port ICS_VIN_Ctrl_ST3
    delegate VSS_Slave_Lvl2_ST3.P_ICS_VIN_ST3 <-> outer port ICS_VIN_ST3
    delegate Diagnostics_RBTM_FL_ST3.P_Awake_Diag_Actv_RBTM_FL_ST3 <-> outer port P_Awake_Diag_Actv_RBTM_FL_ST3
    delegate Diagnostics_RBTM_FL_ST3.P_Awake_Ignition_On_RBTM_FL_ST3 <-> outer port P_Awake_Ignition_On_RBTM_FL_ST3
    delegate Diagnostics_RBTM_FL_ST3.P_Awake_NwStart_RBTM_FL_ST3 <-> outer port P_Awake_NwStart_RBTM_FL_ST3
    delegate Diagnostics_RBTM_FL_ST3.P_WakeupRsn_RBTM_FL_ST3 <-> outer port P_WakeupRsn_RBTM_FL_ST3
    delegate BaseFunction_ECU_RBTM_FL_ST3.R_Ign_Stat_Pr5_ST3 <-> outer port R_Ign_Stat_Pr5_ST3
    delegate VSS_Slave_Lvl2_ST3.R_PN14_DDP_Sw_Stat_ST3 <-> outer port R_PN14_DDP_Sw_Stat_ST3  # Delegation connector for R_PN14_DDP_Sw_Stat_ST3 and R_PN14_DDP_Sw_Stat_ST3
    delegate Autoliv.IG_PresfAct_Adj_Pr5_ST3 <-> outer port R_PresfAct_Adj_Pr5_ST3
    delegate Autoliv.IG_ORC_Impact3_Pr5_ST3 <-> outer port R_ORC_Impact3_Pr5_ST3
    delegate Autoliv.IG_Ign_Stat_Pr5_ST3 <-> outer port R_Ign_Stat_Pr5_ST3
    delegate Autoliv.IF_RBTM_FL_Tgl_ST3 <-> outer port P_RBTM_FL_Tgl_ST3
    delegate Autoliv.IF_RBTM_FL_Disp_Rq_ST3 <-> outer port P_RBTM_FL_Disp_Rq_ST3
    delegate Autoliv.IF_PS_Curve_FL_Stat_ST3 <-> outer port P_PS_Curve_FL_Stat_ST3
    delegate Autoliv.IF_BltSlckDec_Md_XX_Stat_ST3 <-> outer port P_BltSlckDec_Md_XX_Stat_ST3
    connect VSS_Slave_Lvl2_ST3.P_Sec_Event_ST3 -> Diagnostics_RBTM_FR_ST3.R_Sec_Event_ST3, variation-point=post-build-variant-condition{matching-criterion=SideAllocation, value=1}  # Assembly connector for P_Sec_Event_ST3 and R_Sec_Event_ST3
    delegate PRESAFE_Function_Belt_Tensioner_Rt_ST3.P_RBTM_FR_Tgl_ST3 <-> outer port P_RBTM_FR_Tgl_ST3  # Delegation connector for P_RBTM_FR_Tgl_ST3 and P_RBTM_FR_Tgl_ST3
    delegate SeatBeltComf_BeltAdj_FR_ST3.P_RevBltTns_FR_ComCyc_Actv_ST3 <-> outer port P_RevBltTns_FR_ComCyc_Actv_ST3  # Delegation connector for P_RevBltTns_FR_ComCyc_Actv_ST3 and P_RevBltTns_FR_ComCyc_Actv_ST3
    delegate PRESAFE_Function_Belt_Tensioner_Rt_ST3.R_Bckl_Sw_Fx_Stat_Pr5_ST3 <-> outer port R_Bckl_Sw_Fx_Stat_Pr5_ST3  # Delegation connector for R_Bckl_Sw_Fx_Stat_Pr5_ST3 and R_Bckl_Sw_Fx_Stat_Pr5_ST3
    delegate PRESAFE_Function_Belt_Tensioner_Rt_ST3.R_ADAS_Profile_Short_CurvLn_ST3 <-> outer port R_ADAS_Profile_Short_CurvLn_ST3  # Delegation connector for R_ADAS_Profile_Short_CurvLn_ST3 and R_ADAS_Profile_Short_CurvLn_ST3
    delegate BaseFunction_ECU_RBTM_FR_ST3.P_Meas_RBTM_FR_ST3 <-> outer port P_Meas_RBTM_FR_ST3  # Delegation connector for P_Meas_RBTM_FR_ST3 and P_Meas_RBTM_FR_ST3
    delegate SeatBeltComf_BeltAdj_FR_ST3.R_DPC_Md_Rq_ESP_Pr5_ST3 <-> outer port R_DPC_Md_Rq_ESP_Pr5_ST3  # Delegation connector for R_DPC_Md_Rq_ESP_Pr5_ST3 and R_DPC_Md_Rq_ESP_Pr5_ST3
    delegate SeatBeltComf_BeltAdj_FR_ST3.R_PT4_PTCoor_DrvPosn_Gear_Pr5_ST3 <-> outer port R_PT4_PTCoor_DrvPosn_Gear_Pr5_ST3  # Delegation connector for R_PT4_PTCoor_DrvPosn_Gear_Pr5_ST3 and R_PT4_PTCoor_DrvPosn_Gear_Pr5_ST3
    delegate BaseFunction_ECU_RBTM_FR_ST3.P_Awake_Ignition_On_RBTM_FR_ST3 <-> outer port P_Awake_Ignition_On_RBTM_FR_ST3  # Delegation connector for P_Awake_Ignition_On_RBTM_FR_ST3 and P_Awake_Ignition_On_RBTM_FR_ST3
    delegate PRESAFE_Function_Belt_Tensioner_Rt_ST3.R_ORC_Impact3_Pr5_ST3 <-> outer port R_ORC_Impact3_Pr5_ST3  # Delegation connector for R_ORC_Impact3_Pr5_ST3 and R_ORC_Impact3_Pr5_ST3
    delegate BaseFunction_ECU_RBTM_FR_ST3.P_WakeupRsn_RBTM_FR_ST3 <-> outer port P_WakeupRsn_RBTM_FR_ST3  # Delegation connector for P_WakeupRsn_RBTM_FR_ST3 and P_WakeupRsn_RBTM_FR_ST3
    delegate BaseFunction_ECU_RBTM_FR_ST3.R_Develop8_Rq_RBTM_FR_ST3 <-> outer port R_Develop8_Rq_RBTM_FR_ST3  # Delegation connector for R_Develop8_Rq_RBTM_FR_ST3 and R_Develop8_Rq_RBTM_FR_ST3
    delegate PRESAFE_Function_Belt_Tensioner_Rt_ST3.R_ADAS_Prediction_MsgTyp_ST3 <-> outer port R_ADAS_Prediction_MsgTyp_ST3  # Delegation connector for R_ADAS_Prediction_MsgTyp_ST3 and R_ADAS_Prediction_MsgTyp_ST3
    delegate PRESAFE_Function_Belt_Tensioner_Rt_ST3.R_ADAS_Posn_ST3 <-> outer port R_ADAS_Posn_ST3  # Delegation connector for R_ADAS_Posn_ST3 and R_ADAS_Posn_ST3
    delegate PRESAFE_Function_Belt_Tensioner_Rt_ST3.R_PS_Curve_FR_Rq_HU_ST3 <-> outer port R_PS_Curve_FR_Rq_HU_ST3  # Delegation connector for R_PS_Curve_FR_Rq_HU_ST3 and R_PS_Curve_FR_Rq_HU_ST3
    delegate BaseFunction_ECU_RBTM_FR_ST3.P_Develop8_Rs_RBTM_FR_ST3 <-> outer port P_Develop8_Rs_RBTM_FR_ST3  # Delegation connector for P_Develop8_Rs_RBTM_FR_ST3 and P_Develop8_Rs_RBTM_FR_ST3
    delegate SeatBeltComf_BeltAdj_FR_ST3.R_EVC_CfgList_01_08_Pr5_ST3 <-> outer port R_EVC_CfgList_01_08_Pr5_ST3  # Delegation connector for R_EVC_CfgList_01_08_Pr5_ST3 and R_EVC_CfgList_01_08_Pr5_ST3
    delegate SeatBeltComf_BeltAdj_FR_ST3.R_PT4_PTCoor4_Pr5_ST3 <-> outer port R_PT4_PTCoor4_Pr5_ST3  # Delegation connector for R_PT4_PTCoor4_Pr5_ST3 and R_PT4_PTCoor4_Pr5_ST3
    delegate PRESAFE_Function_Belt_Tensioner_Rt_ST3.R_PresfAct_Adj_Pr5_ST3 <-> outer port R_PresfAct_Adj_Pr5_ST3  # Delegation connector for R_PresfAct_Adj_Pr5_ST3 and R_PresfAct_Adj_Pr5_ST3
    delegate PRESAFE_Function_Belt_Tensioner_Rt_ST3.R_RevBltTns_FL_SafeCyc_Actv_ST3 <-> outer port R_RevBltTns_FL_SafeCyc_Actv_ST3  # Delegation connector for R_RevBltTns_FL_SafeCyc_Actv_ST3 and R_RevBltTns_FL_SafeCyc_Actv_ST3
    delegate Diagnostics_RBTM_FR_ST3.R_DidA_ExtTest_Pres_ST3 <-> outer port R_DidA_ExtTest_Pres_ST3  # Delegation connector for R_DidA_ExtTest_Pres_ST3 and R_DidA_ExtTest_Pres_ST3
    delegate Diagnostics_RBTM_FR_ST3.R_PT4_PTCoor4_Pr5_ST3 <-> outer port R_PT4_PTCoor4_Pr5_ST3  # Delegation connector for R_PT4_PTCoor4_Pr5_ST3 and R_PT4_PTCoor4_Pr5_ST3
    delegate Diagnostics_RBTM_FR_ST3.R_PN14_ProdMd_Stat_ST3 <-> outer port R_PN14_ProdMd_Stat_ST3  # Delegation connector for R_PN14_ProdMd_Stat_ST3 and R_PN14_ProdMd_Stat_ST3
    delegate PRESAFE_Function_Belt_Tensioner_Rt_ST3.R_ADAS_ProfShort_ProfTyp_ST3 <-> outer port R_ADAS_ProfShort_ProfTyp_ST3  # Delegation connector for R_ADAS_ProfShort_ProfTyp_ST3 and R_ADAS_ProfShort_ProfTyp_ST3
    delegate Diagnostics_RBTM_FR_ST3.R_PN14_SupBat_Volt_ST3 <-> outer port R_PN14_SupBat_Volt_ST3  # Delegation connector for R_PN14_SupBat_Volt_ST3 and R_PN14_SupBat_Volt_ST3
    delegate Diagnostics_RBTM_FR_ST3.P_ROE <-> outer port P_ROE  # Delegation connector for P_ROE and P_ROE
    delegate SeatBeltComf_BeltAdj_FR_ST3.R_PN14_DDP_Sw_Stat_ST3 <-> outer port R_PN14_DDP_Sw_Stat_ST3  # Delegation connector for R_PN14_DDP_Sw_Stat_ST3 and R_PN14_DDP_Sw_Stat_ST3
    delegate SeatBeltComf_BeltAdj_FR_ST3.R_Bckl_Sw_Fx_Stat_Pr5_ST3 <-> outer port R_Bckl_Sw_Fx_Stat_Pr5_ST3  # Delegation connector for R_Bckl_Sw_Fx_Stat_Pr5_ST3 and R_Bckl_Sw_Fx_Stat_Pr5_ST3
    delegate PRESAFE_Function_Belt_Tensioner_Rt_ST3.R_ELC_Lvr_Stat_Pr5_ST3 <-> outer port R_ELC_Lvr_Stat_Pr5_ST3  # Delegation connector for R_ELC_Lvr_Stat_Pr5_ST3 and R_ELC_Lvr_Stat_Pr5_ST3
    delegate Diagnostics_RBTM_FR_ST3.R_PN14_TransMd_Stat_ST3 <-> outer port R_PN14_TransMd_Stat_ST3  # Delegation connector for R_PN14_TransMd_Stat_ST3 and R_PN14_TransMd_Stat_ST3
    delegate BaseFunction_ECU_RBTM_FR_ST3.P_Awake_NwStart_RBTM_FR_ST3 <-> outer port P_Awake_NwStart_RBTM_FR_ST3  # Delegation connector for P_Awake_NwStart_RBTM_FR_ST3 and P_Awake_NwStart_RBTM_FR_ST3
    delegate PRESAFE_Function_Belt_Tensioner_Rt_ST3.P_RBTM_FR_Disp_Rq_ST3 <-> outer port P_RBTM_FR_Disp_Rq_ST3  # Delegation connector for P_RBTM_FR_Disp_Rq_ST3 and P_RBTM_FR_Disp_Rq_ST3
    delegate Diagnostics_RBTM_FR_ST3.R_DI_Odo_Pr5_ST3 <-> outer port R_DI_Odo_Pr5_ST3  # Delegation connector for R_DI_Odo_Pr5_ST3 and R_DI_Odo_Pr5_ST3
    delegate PRESAFE_Function_Belt_Tensioner_Rt_ST3.R_Navi_RouteGuidance_Stat_ST3 <-> outer port R_Navi_RouteGuidance_Stat_ST3  # Delegation connector for R_Navi_RouteGuidance_Stat_ST3 and R_Navi_RouteGuidance_Stat_ST3
    delegate SeatBeltComf_BeltAdj_FR_ST3.R_BltSlckDec_Md_Rq_HU_ST3 <-> outer port R_BltSlckDec_Md_Rq_HU_ST3  # Delegation connector for R_BltSlckDec_Md_Rq_HU_ST3 and R_BltSlckDec_Md_Rq_HU_ST3
    delegate PRESAFE_Function_Belt_Tensioner_Rt_ST3.P_RevBltTns_FR_SafeCyc_Actv_ST3 <-> outer port P_RevBltTns_FR_SafeCyc_Actv_ST3  # Delegation connector for P_RevBltTns_FR_SafeCyc_Actv_ST3 and P_RevBltTns_FR_SafeCyc_Actv_ST3
    delegate SeatBeltComf_BeltAdj_FR_ST3.R_VehSpd_Disp_ST3 <-> outer port R_VehSpd_Disp_ST3  # Delegation connector for R_VehSpd_Disp_ST3 and R_VehSpd_Disp_ST3
    delegate BaseFunction_ECU_RBTM_FR_ST3.P_Awake_Diag_Actv_RBTM_FR_ST3 <-> outer port P_Awake_Diag_Actv_RBTM_FR_ST3  # Delegation connector for P_Awake_Diag_Actv_RBTM_FR_ST3 and P_Awake_Diag_Actv_RBTM_FR_ST3
    delegate SeatBeltComf_BeltAdj_FR_ST3.R_ORC_Impact3_Pr5_ST3 <-> outer port R_ORC_Impact3_Pr5_ST3  # Delegation connector for R_ORC_Impact3_Pr5_ST3 and R_ORC_Impact3_Pr5_ST3
    delegate SeatBeltComf_BeltAdj_FR_ST3.R_PT4_PTCoor9_Pr5_ST3 <-> outer port R_PT4_PTCoor9_Pr5_ST3  # Delegation connector for R_PT4_PTCoor9_Pr5_ST3 and R_PT4_PTCoor9_Pr5_ST3
    delegate SeatBeltComf_BeltAdj_FR_ST3.R_RevBltTns_FL_ComCyc_Actv_ST3 <-> outer port R_RevBltTns_FL_ComCyc_Actv_ST3  # Delegation connector for R_RevBltTns_FL_ComCyc_Actv_ST3 and R_RevBltTns_FL_ComCyc_Actv_ST3
    delegate PRESAFE_Function_Belt_Tensioner_Rt_ST3.R_ADAS_Meta_ST3 <-> outer port R_ADAS_Meta_ST3  # Delegation connector for R_ADAS_Meta_ST3 and R_ADAS_Meta_ST3
    delegate PRESAFE_Function_Belt_Tensioner_Rt_ST3.P_PS_Curve_FR_Stat_ST3 <-> outer port P_PS_Curve_FR_Stat_ST3  # Delegation connector for P_PS_Curve_FR_Stat_ST3 and P_PS_Curve_FR_Stat_ST3
    delegate PRESAFE_Function_Belt_Tensioner_Rt_ST3.R_BeltHdOvr_XX_Stat_ST3 <-> outer port R_BeltHdOvr_XX_Stat_ST3  # Delegation connector for R_BeltHdOvr_XX_Stat_ST3 and R_BeltHdOvr_XX_Stat_ST3
    delegate PRESAFE_Function_Belt_Tensioner_Rt_ST3.R_EVC_CfgList_01_08_Pr5_ST3 <-> outer port R_EVC_CfgList_01_08_Pr5_ST3  # Delegation connector for R_EVC_CfgList_01_08_Pr5_ST3 and R_EVC_CfgList_01_08_Pr5_ST3
    delegate SeatBeltComf_BeltAdj_FR_ST3.R_CLkS_DrRltch_Stat_Pr5_ST3 <-> outer port R_CLkS_DrRltch_Stat_Pr5_ST3  # Delegation connector for R_CLkS_DrRltch_Stat_Pr5_ST3 and R_CLkS_DrRltch_Stat_Pr5_ST3
    delegate SeatBeltComf_BeltAdj_FR_ST3.R_PresfAct_Adj_Pr5_ST3 <-> outer port R_PresfAct_Adj_Pr5_ST3  # Delegation connector for R_PresfAct_Adj_Pr5_ST3 and R_PresfAct_Adj_Pr5_ST3
    delegate SeatBeltComf_BeltAdj_FR_ST3.R_ORC_Impact2_Pr5_ST3 <-> outer port R_ORC_Impact2_Pr5_ST3  # Delegation connector for R_ORC_Impact2_Pr5_ST3 and R_ORC_Impact2_Pr5_ST3
    delegate Diagnostics_RBTM_FR_ST3.R_Ign_Stat_Pr5_ST3 <-> outer port R_Ign_Stat_Pr5_ST3  # Delegation connector for R_Ign_Stat_Pr5_ST3 and R_Ign_Stat_Pr5_ST3
    delegate BaseFunction_ECU_RBTM_FR_ST3.P_ECU_Id_RBTM_FR_ST3 <-> outer port P_ECU_Id_RBTM_FR_ST3  # Delegation connector for P_ECU_Id_RBTM_FR_ST3 and P_ECU_Id_RBTM_FR_ST3
    delegate PRESAFE_Function_Belt_Tensioner_Rt_ST3.R_Ign_Stat_Pr5_ST3 <-> outer port R_Ign_Stat_Pr5_ST3  # Delegation connector for R_Ign_Stat_Pr5_ST3 and R_Ign_Stat_Pr5_ST3
    delegate Autoliv.P_PS_Curve_FR_Stat_ST3 <-> outer port P_PS_Curve_FR_Stat_ST3
    delegate Autoliv.P_RBTM_FR_Tgl_ST3 <-> outer port P_RBTM_FR_Tgl_ST3
    delegate Autoliv.P_RBTM_FR_Disp_Rq_ST3 <-> outer port P_RBTM_FR_Disp_Rq_ST3
    delegate VSS_Slave_Lvl2_ST3.P_VSS_TP_SecTickCount_ST3 <-> outer port P_VSS_TP_SecTickCount_ST3
    delegate Autoliv.IG_ORC_Impact2_Pr5_ST3 <-> outer port R_ORC_Impact2_Pr5_ST3
    delegate Autoliv.P_Meas_RBTM_FL_ST3 <-> outer port P_Meas_RBTM_FL_ST3
    delegate Autoliv.P_Meas_RBTM_FR_ST3 <-> outer port P_Meas_RBTM_FR_ST3
    delegate PRESAFE_Function_Belt_Tensioner_Lt_ST3.P_RBTMFL_SP_FctPrecond_Stat_ST35 <-> outer port P_RBTMFL_SP_FctPrecond_Stat_ST35  # Delegation connector for P_RBTMFL_SP_FctPrecond_Stat_ST35 and P_RBTMFL_SP_FctPrecond_Stat_ST35
    delegate PRESAFE_Function_Belt_Tensioner_Lt_ST3.P_RBTMFL_SP_ActvClient_ST35 <-> outer port P_RBTMFL_SP_ActvClient_ST35  # Delegation connector for P_RBTMFL_SP_ActvClient_ST35 and P_RBTMFL_SP_ActvClient_ST35
    delegate PRESAFE_Function_Belt_Tensioner_Lt_ST3.P_RBTMFL_Actv_Lvl_ST35 <-> outer port P_RBTMFL_Actv_Lvl_ST35  # Delegation connector for P_RBTMFL_Actv_Lvl_ST35 and P_RBTMFL_Actv_Lvl_ST35
    delegate PRESAFE_Function_Belt_Tensioner_Lt_ST3.R_SBeltTens_SP_Lvl_Pr5_ST3 <-> outer port R_SBeltTens_SP_Lvl_Pr5_ST3  # Delegation connector for R_SBeltTens_SP_Lvl_Pr5_ST3 and R_SBeltTens_SP_Lvl_Pr5_ST3
    delegate PRESAFE_Function_Belt_Tensioner_Rt_ST3.R_SBeltTens_SP_Lvl_Pr5_ST3 <-> outer port R_SBeltTens_SP_Lvl_Pr5_ST3  # Delegation connector for R_SBeltTens_SP_Lvl_Pr5_ST3 and R_SBeltTens_SP_Lvl_Pr5_ST3
    delegate PRESAFE_Function_Belt_Tensioner_Rt_ST3.P_RBTMFR_SP_FctPrecond_Stat_ST35 <-> outer port P_RBTMFR_SP_FctPrecond_Stat_ST35  # Delegation connector for P_RBTMFR_SP_FctPrecond_Stat_ST35 and P_RBTMFR_SP_FctPrecond_Stat_ST35
    delegate PRESAFE_Function_Belt_Tensioner_Rt_ST3.P_RBTMFR_SP_ActvClient_ST35 <-> outer port P_RBTMFR_SP_ActvClient_ST35  # Delegation connector for P_RBTMFR_SP_ActvClient_ST35 and P_RBTMFR_SP_ActvClient_ST35
    delegate PRESAFE_Function_Belt_Tensioner_Rt_ST3.P_RBTMFR_Actv_Lvl_ST35 <-> outer port P_RBTMFR_Actv_Lvl_ST35  # Delegation connector for P_RBTMFR_Actv_Lvl_ST35 and P_RBTMFR_Actv_Lvl_ST35
    delegate Autoliv.R_SBeltTens_SP_Lvl_Pr5_ST3 <-> outer port R_SBeltTens_SP_Lvl_Pr5_ST3
    delegate Autoliv.RBTMFR_Actv_Lvl_ST35 <-> outer port P_RBTMFR_Actv_Lvl_ST35
    delegate Autoliv.RBTMFL_Actv_Lvl_ST35 <-> outer port P_RBTMFL_Actv_Lvl_ST35
    delegate Autoliv.R_PS_Curve_FR_Rq_HU_ST3 <-> outer port R_PS_Curve_FR_Rq_HU_ST3
    delegate Autoliv.R_PS_Curve_FL_Rq_HU_ST3 <-> outer port R_PS_Curve_FL_Rq_HU_ST3
    delegate Autoliv.P_RBTMFL_SP_ActvClient_ST35 <-> outer port P_RBTMFL_SP_ActvClient_ST35
    delegate Autoliv.P_RBTMFR_SP_ActvClient_ST35 <-> outer port P_RBTMFR_SP_ActvClient_ST35
    delegate Autoliv.P_RBTMFL_SP_FctPrecond_Stat_ST35 <-> outer port P_RBTMFL_SP_FctPrecond_Stat_ST35
    delegate Autoliv.P_RBTMFR_SP_FctPrecond_Stat_ST35 <-> outer port P_RBTMFR_SP_FctPrecond_Stat_ST35
    delegate Autoliv.R_Bckl_Sw_Fx_Stat_Pr5_ST3 <-> outer port R_Bckl_Sw_Fx_Stat_Pr5_ST3
    delegate Autoliv.R_DidA_ExtTest_Pres_ST3 <-> outer port R_DidA_ExtTest_Pres_ST3
    delegate Autoliv.R_EVC_CfgList_01_08_Pr5_ST3 <-> outer port R_EVC_CfgList_01_08_Pr5_ST3
    delegate Autoliv.R_PN14_DDP_Sw_Stat_ST3 <-> outer port R_PN14_DDP_Sw_Stat_ST3
    delegate Autoliv.R_PN14_ProdMd_Stat_ST3 <-> outer port R_PN14_ProdMd_Stat_ST3
    delegate Autoliv.R_BeltHdOvr_XX_Stat_ST3 <-> outer port R_BeltHdOvr_XX_Stat_ST3
    delegate Autoliv.R_PN14_SupBat_Volt_ST3 <-> outer port R_PN14_SupBat_Volt_ST3
    delegate Autoliv.R_PT4_PTCoor_DrvPosn_Gear_Pr5_ST3 <-> outer port R_PT4_PTCoor_DrvPosn_Gear_Pr5_ST3
    delegate Autoliv.R_PT4_PTCoor4_Pr5_ST3 <-> outer port R_PT4_PTCoor4_Pr5_ST3
    delegate Autoliv.R_PN14_TransMd_Stat_ST3 <-> outer port R_PN14_TransMd_Stat_ST3
    delegate Autoliv.R_BltSlckDec_Md_Rq_HU_ST3 <-> outer port R_BltSlckDec_Md_Rq_HU_ST3
    delegate SeatBeltComf_BeltAdj_FL_ST3.P_BltSlckDec_Md_XX_Stat_ST3 <-> outer port P_BltSlckDec_Md_XX_Stat_ST3  # Delegation connector for P_BltSlckDec_Md_XX_Stat_ST3 and P_BltSlckDec_Md_XX_Stat_ST3
    delegate SeatBeltComf_BeltAdj_FR_ST3.P_BltSlckDec_Md_XX_Stat_ST3 <-> outer port P_BltSlckDec_Md_XX_Stat_ST3  # Delegation connector for P_BltSlckDec_Md_XX_Stat_ST3 and P_BltSlckDec_Md_XX_Stat_ST3
    connect Diagnostics_RBTM_FL_ST3.pseSystemTime -> Autoliv.pclSystemTime
package /EndToEndProtections
  end to end protection set EndToEndProtectionSet
